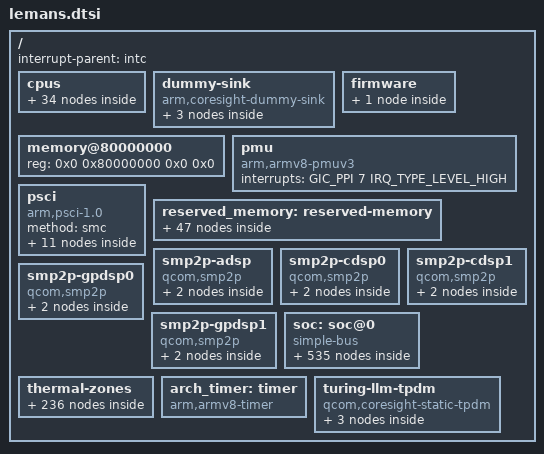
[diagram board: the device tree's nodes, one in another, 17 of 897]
// SPDX-License-Identifier: BSD-3-Clause
/*
 * Copyright (c) 2023, Linaro Limited
 * Copyright (c) 2024 Qualcomm Innovation Center, Inc. All rights reserved.
 */

#include <dt-bindings/interrupt-controller/arm-gic.h>
#include <dt-bindings/dma/qcom-gpi.h>
#include <dt-bindings/mailbox/qcom-ipcc.h>
#include <dt-bindings/firmware/qcom,scm.h>
#include <dt-bindings/soc/qcom,gpr.h>
#include <dt-bindings/thermal/qcom,pas.h>
#include <dt-bindings/thermal/thermal.h>

/ {
	interrupt-parent = <&intc>;

	#address-cells = <2>;
	#size-cells = <2>;

	cpus {
		#address-cells = <2>;
		#size-cells = <0>;

		cpu0: cpu@0 {
			device_type = "cpu";
			compatible = "qcom,kryo";
			reg = <0x0 0x0>;
			enable-method = "psci";
			power-domains = <&cpu_pd0>;
			power-domain-names = "psci";
			qcom,freq-domain = <&cpufreq_hw 0>;
			next-level-cache = <&l2_0>;
			capacity-dmips-mhz = <1024>;
			#cooling-cells = <2>;
			dynamic-power-coefficient = <100>;
			l2_0: l2-cache {
				compatible = "cache";
				cache-level = <2>;
				cache-unified;
				next-level-cache = <&l3_0>;
				l3_0: l3-cache {
					compatible = "cache";
					cache-level = <3>;
					cache-unified;
				};
			};
		};

		cpu1: cpu@100 {
			device_type = "cpu";
			compatible = "qcom,kryo";
			reg = <0x0 0x100>;
			enable-method = "psci";
			power-domains = <&cpu_pd1>;
			power-domain-names = "psci";
			qcom,freq-domain = <&cpufreq_hw 0>;
			next-level-cache = <&l2_1>;
			capacity-dmips-mhz = <1024>;
			#cooling-cells = <2>;
			dynamic-power-coefficient = <100>;
			l2_1: l2-cache {
				compatible = "cache";
				cache-level = <2>;
				cache-unified;
				next-level-cache = <&l3_0>;
			};
		};

		cpu2: cpu@200 {
			device_type = "cpu";
			compatible = "qcom,kryo";
			reg = <0x0 0x200>;
			enable-method = "psci";
			power-domains = <&cpu_pd2>;
			power-domain-names = "psci";
			qcom,freq-domain = <&cpufreq_hw 0>;
			next-level-cache = <&l2_2>;
			capacity-dmips-mhz = <1024>;
			#cooling-cells = <2>;
			dynamic-power-coefficient = <100>;
			l2_2: l2-cache {
				compatible = "cache";
				cache-level = <2>;
				cache-unified;
				next-level-cache = <&l3_0>;
			};
		};

		cpu3: cpu@300 {
			device_type = "cpu";
			compatible = "qcom,kryo";
			reg = <0x0 0x300>;
			enable-method = "psci";
			power-domains = <&cpu_pd3>;
			power-domain-names = "psci";
			qcom,freq-domain = <&cpufreq_hw 0>;
			next-level-cache = <&l2_3>;
			capacity-dmips-mhz = <1024>;
			#cooling-cells = <2>;
			dynamic-power-coefficient = <100>;
			l2_3: l2-cache {
				compatible = "cache";
				cache-level = <2>;
				cache-unified;
				next-level-cache = <&l3_0>;
			};
		};

		cpu4: cpu@10000 {
			device_type = "cpu";
			compatible = "qcom,kryo";
			reg = <0x0 0x10000>;
			enable-method = "psci";
			power-domains = <&cpu_pd4>;
			power-domain-names = "psci";
			qcom,freq-domain = <&cpufreq_hw 1>;
			next-level-cache = <&l2_4>;
			capacity-dmips-mhz = <1024>;
			#cooling-cells = <2>;
			dynamic-power-coefficient = <100>;
			l2_4: l2-cache {
				compatible = "cache";
				cache-level = <2>;
				cache-unified;
				next-level-cache = <&l3_1>;
				l3_1: l3-cache {
					compatible = "cache";
					cache-level = <3>;
					cache-unified;
				};

			};
		};

		cpu5: cpu@10100 {
			device_type = "cpu";
			compatible = "qcom,kryo";
			reg = <0x0 0x10100>;
			enable-method = "psci";
			power-domains = <&cpu_pd5>;
			power-domain-names = "psci";
			qcom,freq-domain = <&cpufreq_hw 1>;
			next-level-cache = <&l2_5>;
			capacity-dmips-mhz = <1024>;
			#cooling-cells = <2>;
			dynamic-power-coefficient = <100>;
			l2_5: l2-cache {
				compatible = "cache";
				cache-level = <2>;
				cache-unified;
				next-level-cache = <&l3_1>;
			};
		};

		cpu6: cpu@10200 {
			device_type = "cpu";
			compatible = "qcom,kryo";
			reg = <0x0 0x10200>;
			enable-method = "psci";
			power-domains = <&cpu_pd6>;
			power-domain-names = "psci";
			qcom,freq-domain = <&cpufreq_hw 1>;
			next-level-cache = <&l2_6>;
			capacity-dmips-mhz = <1024>;
			#cooling-cells = <2>;
			dynamic-power-coefficient = <100>;
			l2_6: l2-cache {
				compatible = "cache";
				cache-level = <2>;
				cache-unified;
				next-level-cache = <&l3_1>;
			};
		};

		cpu7: cpu@10300 {
			device_type = "cpu";
			compatible = "qcom,kryo";
			reg = <0x0 0x10300>;
			enable-method = "psci";
			power-domains = <&cpu_pd7>;
			power-domain-names = "psci";
			qcom,freq-domain = <&cpufreq_hw 1>;
			next-level-cache = <&l2_7>;
			capacity-dmips-mhz = <1024>;
			#cooling-cells = <2>;
			dynamic-power-coefficient = <100>;
			l2_7: l2-cache {
				compatible = "cache";
				cache-level = <2>;
				cache-unified;
				next-level-cache = <&l3_1>;
			};
		};

		cpu-map {
			cluster0 {
				core0 {
					cpu = <&cpu0>;
				};

				core1 {
					cpu = <&cpu1>;
				};

				core2 {
					cpu = <&cpu2>;
				};

				core3 {
					cpu = <&cpu3>;
				};
			};

			cluster1 {
				core0 {
					cpu = <&cpu4>;
				};

				core1 {
					cpu = <&cpu5>;
				};

				core2 {
					cpu = <&cpu6>;
				};

				core3 {
					cpu = <&cpu7>;
				};
			};
		};

		idle-states {
			entry-method = "psci";

			gold_rail_cpu_sleep_0: cpu-sleep-0 {
				compatible = "arm,idle-state";
				idle-state-name = "gold-rail-power-collapse";
				arm,psci-suspend-param = <0x40000004>;
				entry-latency-us = <702>;
				exit-latency-us = <1061>;
				min-residency-us = <4488>;
				local-timer-stop;
			};
		};

		domain-idle-states {
			cluster_sleep_gold: cluster-sleep-0 {
				compatible = "domain-idle-state";
				arm,psci-suspend-param = <0x41000044>;
				entry-latency-us = <2752>;
				exit-latency-us = <3048>;
				min-residency-us = <6118>;
			};

			cluster_sleep_apss_rsc_pc: cluster-sleep-1 {
				compatible = "domain-idle-state";
				arm,psci-suspend-param = <0x42000144>;
				entry-latency-us = <3263>;
				exit-latency-us = <6562>;
				min-residency-us = <9987>;
			};
		};
	};

	dummy-sink {
		compatible = "arm,coresight-dummy-sink";

		in-ports {
			port {
				eud_in: endpoint {
					remote-endpoint =
					<&swao_rep_out1>;
				};
			};
		};
	};

	firmware: firmware {
		scm: scm {
			compatible = "qcom,scm-sa8775p", "qcom,scm";
			qcom,dload-mode = <&tcsr 0x13000>;
			sram = <&minidump_config>;
		};
	};

	/* Will be updated by the bootloader. */
	memory@80000000 {
		device_type = "memory";
		reg = <0x0 0x80000000 0x0 0x0>;
	};

	pmu {
		compatible = "arm,armv8-pmuv3";
		interrupts = <GIC_PPI 7 IRQ_TYPE_LEVEL_HIGH>;
	};

	psci {
		compatible = "arm,psci-1.0";
		method = "smc";

		cpu_pd0: power-domain-cpu0 {
			#power-domain-cells = <0>;
			power-domains = <&cluster_0_pd>;
			domain-idle-states = <&gold_rail_cpu_sleep_0>;
		};

		cpu_pd1: power-domain-cpu1 {
			#power-domain-cells = <0>;
			power-domains = <&cluster_0_pd>;
			domain-idle-states = <&gold_rail_cpu_sleep_0>;
		};

		cpu_pd2: power-domain-cpu2 {
			#power-domain-cells = <0>;
			power-domains = <&cluster_0_pd>;
			domain-idle-states = <&gold_rail_cpu_sleep_0>;
		};

		cpu_pd3: power-domain-cpu3 {
			#power-domain-cells = <0>;
			power-domains = <&cluster_0_pd>;
			domain-idle-states = <&gold_rail_cpu_sleep_0>;
		};

		cpu_pd4: power-domain-cpu4 {
			#power-domain-cells = <0>;
			power-domains = <&cluster_1_pd>;
			domain-idle-states = <&gold_rail_cpu_sleep_0>;
		};

		cpu_pd5: power-domain-cpu5 {
			#power-domain-cells = <0>;
			power-domains = <&cluster_1_pd>;
			domain-idle-states = <&gold_rail_cpu_sleep_0>;
		};

		cpu_pd6: power-domain-cpu6 {
			#power-domain-cells = <0>;
			power-domains = <&cluster_1_pd>;
			domain-idle-states = <&gold_rail_cpu_sleep_0>;
		};

		cpu_pd7: power-domain-cpu7 {
			#power-domain-cells = <0>;
			power-domains = <&cluster_1_pd>;
			domain-idle-states = <&gold_rail_cpu_sleep_0>;
		};

		cluster_0_pd: power-domain-cluster0 {
			#power-domain-cells = <0>;
			domain-idle-states = <&cluster_sleep_gold>;
			power-domains = <&system_pd>;
		};

		cluster_1_pd: power-domain-cluster1 {
			#power-domain-cells = <0>;
			domain-idle-states = <&cluster_sleep_gold>;
			power-domains = <&system_pd>;
		};

		system_pd: power-domain-system {
			#power-domain-cells = <0>;
			domain-idle-states = <&cluster_sleep_apss_rsc_pc>;
		};
	};

	reserved_memory: reserved-memory {
		#address-cells = <2>;
		#size-cells = <2>;
		ranges;

		sail_ss_mem: sail-ss@80000000 {
			reg = <0x0 0x80000000 0x0 0x10000000>;
			no-map;
		};

		hyp_mem: hyp@90000000 {
			reg = <0x0 0x90000000 0x0 0x600000>;
			no-map;
		};

		xbl_boot_mem: xbl-boot@90600000 {
			reg = <0x0 0x90600000 0x0 0x200000>;
			no-map;
		};

		aop_image_mem: aop-image@90800000 {
			reg = <0x0 0x90800000 0x0 0x60000>;
			no-map;
		};

		aop_cmd_db_mem: aop-cmd-db@90860000 {
			compatible = "qcom,cmd-db";
			reg = <0x0 0x90860000 0x0 0x20000>;
			no-map;
		};

		uefi_log: uefi-log@908b0000 {
			reg = <0x0 0x908b0000 0x0 0x10000>;
			no-map;
		};

		ddr_training_checksum: ddr-training-checksum@908c0000 {
			reg = <0x0 0x908c0000 0x0 0x1000>;
			no-map;
		};

		reserved_mem: reserved@908f0000 {
			reg = <0x0 0x908f0000 0x0 0xe000>;
			no-map;
		};

		secdata_apss_mem: secdata-apss@908fe000 {
			reg = <0x0 0x908fe000 0x0 0x2000>;
			no-map;
		};

		smem_mem: smem@90900000 {
			compatible = "qcom,smem";
			reg = <0x0 0x90900000 0x0 0x200000>;
			no-map;
			hwlocks = <&tcsr_mutex 3>;
		};

		tz_sail_mailbox_mem: tz-sail-mailbox@90c00000 {
			reg = <0x0 0x90c00000 0x0 0x100000>;
			no-map;
		};

		sail_mailbox_mem: sail-ss@90d00000 {
			reg = <0x0 0x90d00000 0x0 0x100000>;
			no-map;
		};

		sail_ota_mem: sail-ss@90e00000 {
			reg = <0x0 0x90e00000 0x0 0x300000>;
			no-map;
		};

		gunyah_md_mem: gunyah-md@91a80000 {
			reg = <0x0 0x91a80000 0x0 0x80000>;
			no-map;
		};

		aoss_backup_mem: aoss-backup@91b00000 {
			reg = <0x0 0x91b00000 0x0 0x40000>;
			no-map;
		};

		cpucp_backup_mem: cpucp-backup@91b40000 {
			reg = <0x0 0x91b40000 0x0 0x40000>;
			no-map;
		};

		tz_config_backup_mem: tz-config-backup@91b80000 {
			reg = <0x0 0x91b80000 0x0 0x10000>;
			no-map;
		};

		ddr_training_data_mem: ddr-training-data@91b90000 {
			reg = <0x0 0x91b90000 0x0 0x10000>;
			no-map;
		};

		cdt_data_backup_mem: cdt-data-backup@91ba0000 {
			reg = <0x0 0x91ba0000 0x0 0x1000>;
			no-map;
		};

		lpass_machine_learning_mem: lpass-machine-learning@93b00000 {
			reg = <0x0 0x93b00000 0x0 0xf00000>;
			no-map;
		};

		adsp_rpc_remote_heap_mem: adsp-rpc-remote-heap@94a00000 {
			reg = <0x0 0x94a00000 0x0 0x800000>;
			no-map;
		};

		pil_camera_mem: pil-camera@95200000 {
			reg = <0x0 0x95200000 0x0 0x700000>;
			no-map;
		};

		pil_adsp_mem: pil-adsp@95900000 {
			reg = <0x0 0x95900000 0x0 0x1e00000>;
			no-map;
		};

		q6_adsp_dtb_mem: q6-adsp-dtb@97700000 {
			reg = <0x0 0x97700000 0x0 0x80000>;
			no-map;
		};

		q6_gdsp0_dtb_mem: q6-gdsp0-dtb@97780000 {
			reg = <0x0 0x97780000 0x0 0x80000>;
			no-map;
		};

		pil_gdsp0_mem: pil-gdsp0@97800000 {
			reg = <0x0 0x97800000 0x0 0x1e00000>;
			no-map;
		};

		pil_gdsp1_mem: pil-gdsp1@99600000 {
			reg = <0x0 0x99600000 0x0 0x1e00000>;
			no-map;
		};

		q6_gdsp1_dtb_mem: q6-gdsp1-dtb@9b400000 {
			reg = <0x0 0x9b400000 0x0 0x80000>;
			no-map;
		};

		q6_cdsp0_dtb_mem: q6-cdsp0-dtb@9b480000 {
			reg = <0x0 0x9b480000 0x0 0x80000>;
			no-map;
		};

		pil_cdsp0_mem: pil-cdsp0@9b500000 {
			reg = <0x0 0x9b500000 0x0 0x1e00000>;
			no-map;
		};

		pil_gpu_mem: pil-gpu@9d300000 {
			reg = <0x0 0x9d300000 0x0 0x2000>;
			no-map;
		};

		q6_cdsp1_dtb_mem: q6-cdsp1-dtb@9d380000 {
			reg = <0x0 0x9d380000 0x0 0x80000>;
			no-map;
		};

		pil_cdsp1_mem: pil-cdsp1@9d400000 {
			reg = <0x0 0x9d400000 0x0 0x1e00000>;
			no-map;
		};

		pil_cvp_mem: pil-cvp@9f200000 {
			reg = <0x0 0x9f200000 0x0 0x700000>;
			no-map;
		};

		pil_video_mem: pil-video@9f900000 {
			reg = <0x0 0x9f900000 0x0 0x1000000>;
			no-map;
		};

		firmware_mem: firmware-region@b0000000 {
			reg = <0x0 0xb0000000 0x0 0x800000>;
			no-map;
		};

		scmi_mem: scmi-region@d0000000 {
			reg = <0x0 0xd0000000 0x0 0x40000>;
			no-map;
		};

		firmware_logs_mem: firmware-logs@d0040000 {
			reg = <0x0 0xd0040000 0x0 0x10000>;
			no-map;
		};

		firmware_audio_mem: firmware-audio@d0050000 {
			reg = <0x0 0xd0050000 0x0 0x4000>;
			no-map;
		};

		firmware_reserved_mem: firmware-reserved@d0054000 {
			reg = <0x0 0xd0054000 0x0 0x9c000>;
			no-map;
		};

		firmware_quantum_test_mem: firmware-quantum-test@d00f0000 {
			reg = <0x0 0xd00f0000 0x0 0x10000>;
			no-map;
		};

		tags_mem: tags@d0100000 {
			reg = <0x0 0xd0100000 0x0 0x1200000>;
			no-map;
		};

		qtee_mem: qtee@d1300000 {
			reg = <0x0 0xd1300000 0x0 0x500000>;
			no-map;
		};

		deepsleep_backup_mem: deepsleep-backup@d1800000 {
			reg = <0x0 0xd1800000 0x0 0x100000>;
			no-map;
		};

		trusted_apps_mem: trusted-apps@d1900000 {
			reg = <0x0 0xd1900000 0x0 0x1c00000>;
			no-map;
		};

		tz_stat_mem: tz-stat@db100000 {
			reg = <0x0 0xdb100000 0x0 0x100000>;
			no-map;
		};

		cpucp_fw_mem: cpucp-fw@db200000 {
			reg = <0x0 0xdb200000 0x0 0x100000>;
			no-map;
		};
	};

	smp2p-adsp {
		compatible = "qcom,smp2p";
		qcom,smem = <443>, <429>;
		interrupts-extended = <&ipcc IPCC_CLIENT_LPASS
					     IPCC_MPROC_SIGNAL_SMP2P
					     IRQ_TYPE_EDGE_RISING>;
		mboxes = <&ipcc IPCC_CLIENT_LPASS IPCC_MPROC_SIGNAL_SMP2P>;

		qcom,local-pid = <0>;
		qcom,remote-pid = <2>;

		smp2p_adsp_out: master-kernel {
			qcom,entry-name = "master-kernel";
			#qcom,smem-state-cells = <1>;
		};

		smp2p_adsp_in: slave-kernel {
			qcom,entry-name = "slave-kernel";
			interrupt-controller;
			#interrupt-cells = <2>;
		};
	};

	smp2p-cdsp0 {
		compatible = "qcom,smp2p";
		qcom,smem = <94>, <432>;
		interrupts-extended = <&ipcc IPCC_CLIENT_CDSP
					     IPCC_MPROC_SIGNAL_SMP2P
					     IRQ_TYPE_EDGE_RISING>;
		mboxes = <&ipcc IPCC_CLIENT_CDSP IPCC_MPROC_SIGNAL_SMP2P>;

		qcom,local-pid = <0>;
		qcom,remote-pid = <5>;

		smp2p_cdsp0_out: master-kernel {
			qcom,entry-name = "master-kernel";
			#qcom,smem-state-cells = <1>;
		};

		smp2p_cdsp0_in: slave-kernel {
			qcom,entry-name = "slave-kernel";
			interrupt-controller;
			#interrupt-cells = <2>;
		};
	};

	smp2p-cdsp1 {
		compatible = "qcom,smp2p";
		qcom,smem = <617>, <616>;
		interrupts-extended = <&ipcc IPCC_CLIENT_NSP1
					     IPCC_MPROC_SIGNAL_SMP2P
					     IRQ_TYPE_EDGE_RISING>;
		mboxes = <&ipcc IPCC_CLIENT_NSP1 IPCC_MPROC_SIGNAL_SMP2P>;

		qcom,local-pid = <0>;
		qcom,remote-pid = <12>;

		smp2p_cdsp1_out: master-kernel {
			qcom,entry-name = "master-kernel";
			#qcom,smem-state-cells = <1>;
		};

		smp2p_cdsp1_in: slave-kernel {
			qcom,entry-name = "slave-kernel";
			interrupt-controller;
			#interrupt-cells = <2>;
		};
	};

	smp2p-gpdsp0 {
		compatible = "qcom,smp2p";
		qcom,smem = <617>, <616>;
		interrupts-extended = <&ipcc IPCC_CLIENT_GPDSP0
					     IPCC_MPROC_SIGNAL_SMP2P
					     IRQ_TYPE_EDGE_RISING>;
		mboxes = <&ipcc IPCC_CLIENT_GPDSP0 IPCC_MPROC_SIGNAL_SMP2P>;

		qcom,local-pid = <0>;
		qcom,remote-pid = <17>;

		smp2p_gpdsp0_out: master-kernel {
			qcom,entry-name = "master-kernel";
			#qcom,smem-state-cells = <1>;
		};

		smp2p_gpdsp0_in: slave-kernel {
			qcom,entry-name = "slave-kernel";
			interrupt-controller;
			#interrupt-cells = <2>;
		};
	};

	smp2p-gpdsp1 {
		compatible = "qcom,smp2p";
		qcom,smem = <617>, <616>;
		interrupts-extended = <&ipcc IPCC_CLIENT_GPDSP1
					     IPCC_MPROC_SIGNAL_SMP2P
					     IRQ_TYPE_EDGE_RISING>;
		mboxes = <&ipcc IPCC_CLIENT_GPDSP1 IPCC_MPROC_SIGNAL_SMP2P>;

		qcom,local-pid = <0>;
		qcom,remote-pid = <18>;

		smp2p_gpdsp1_out: master-kernel {
			qcom,entry-name = "master-kernel";
			#qcom,smem-state-cells = <1>;
		};

		smp2p_gpdsp1_in: slave-kernel {
			qcom,entry-name = "slave-kernel";
			interrupt-controller;
			#interrupt-cells = <2>;
		};
	};

	soc: soc@0 {
		compatible = "simple-bus";
		#address-cells = <2>;
		#size-cells = <2>;
		ranges = <0 0 0 0 0x10 0>;

		ipcc: mailbox@408000 {
			compatible = "qcom,sa8775p-ipcc", "qcom,ipcc";
			reg = <0x0 0x00408000 0x0 0x1000>;
			interrupts = <GIC_SPI 229 IRQ_TYPE_LEVEL_HIGH>;
			interrupt-controller;
			#interrupt-cells = <3>;
			#mbox-cells = <2>;
		};

		qfprom: efuse@784000 {
			compatible = "qcom,sa8775p-qfprom", "qcom,qfprom";
			reg = <0x0 0x00784000 0x0 0x3000>;
			#address-cells = <1>;
			#size-cells = <1>;

			gpu_speed_bin: gpu-speed-bin@240c {
				reg = <0x240c 0x1>;
				bits = <0 8>;
			};
		};

		gpi_dma2: dma-controller@800000 {
			compatible = "qcom,sa8775p-gpi-dma", "qcom,sm6350-gpi-dma";
			reg = <0x0 0x00800000 0x0 0x60000>;
			#dma-cells = <3>;
			interrupts = <GIC_SPI 588 IRQ_TYPE_LEVEL_HIGH>,
				     <GIC_SPI 589 IRQ_TYPE_LEVEL_HIGH>,
				     <GIC_SPI 590 IRQ_TYPE_LEVEL_HIGH>,
				     <GIC_SPI 591 IRQ_TYPE_LEVEL_HIGH>,
				     <GIC_SPI 592 IRQ_TYPE_LEVEL_HIGH>,
				     <GIC_SPI 593 IRQ_TYPE_LEVEL_HIGH>,
				     <GIC_SPI 594 IRQ_TYPE_LEVEL_HIGH>,
				     <GIC_SPI 595 IRQ_TYPE_LEVEL_HIGH>,
				     <GIC_SPI 596 IRQ_TYPE_LEVEL_HIGH>,
				     <GIC_SPI 597 IRQ_TYPE_LEVEL_HIGH>,
				     <GIC_SPI 598 IRQ_TYPE_LEVEL_HIGH>,
				     <GIC_SPI 599 IRQ_TYPE_LEVEL_HIGH>;
			dma-channels = <12>;
			dma-channel-mask = <0xfff>;
			iommus = <&apps_smmu 0x5b6 0x0>;
			status = "disabled";
		};

		qupv3_id_2: geniqup@8c0000 {
			compatible = "qcom,geni-se-qup";
			reg = <0x0 0x008c0000 0x0 0x6000>;
			ranges;
			iommus = <&apps_smmu 0x5a3 0x0>;
			#address-cells = <2>;
			#size-cells = <2>;
			status = "disabled";

			i2c14: i2c@880000 {
				compatible = "qcom,geni-i2c";
				reg = <0x0 0x880000 0x0 0x4000>;
				#address-cells = <1>;
				#size-cells = <0>;
				interrupts = <GIC_SPI 373 IRQ_TYPE_LEVEL_HIGH>;
				dmas = <&gpi_dma2 0 0 QCOM_GPI_I2C>,
				       <&gpi_dma2 1 0 QCOM_GPI_I2C>;
				dma-names = "tx",
					    "rx";
				status = "disabled";
			};

			spi14: spi@880000 {
				compatible = "qcom,geni-spi";
				reg = <0x0 0x880000 0x0 0x4000>;
				#address-cells = <1>;
				#size-cells = <0>;
				interrupts = <GIC_SPI 373 IRQ_TYPE_LEVEL_HIGH>;
				dmas = <&gpi_dma2 0 0 QCOM_GPI_SPI>,
				       <&gpi_dma2 1 0 QCOM_GPI_SPI>;
				dma-names = "tx",
					    "rx";
				status = "disabled";
			};

			uart14: serial@880000 {
				compatible = "qcom,geni-uart";
				reg = <0x0 0x00880000 0x0 0x4000>;
				interrupts = <GIC_SPI 373 IRQ_TYPE_LEVEL_HIGH>;
				status = "disabled";
			};

			i2c15: i2c@884000 {
				compatible = "qcom,geni-i2c";
				reg = <0x0 0x884000 0x0 0x4000>;
				#address-cells = <1>;
				#size-cells = <0>;
				interrupts = <GIC_SPI 583 IRQ_TYPE_LEVEL_HIGH>;
				dmas = <&gpi_dma2 0 1 QCOM_GPI_I2C>,
				       <&gpi_dma2 1 1 QCOM_GPI_I2C>;
				dma-names = "tx",
					    "rx";
				status = "disabled";
			};

			spi15: spi@884000 {
				compatible = "qcom,geni-spi";
				reg = <0x0 0x884000 0x0 0x4000>;
				#address-cells = <1>;
				#size-cells = <0>;
				interrupts = <GIC_SPI 583 IRQ_TYPE_LEVEL_HIGH>;
				dmas = <&gpi_dma2 0 1 QCOM_GPI_SPI>,
				       <&gpi_dma2 1 1 QCOM_GPI_SPI>;
				dma-names = "tx",
					    "rx";
				status = "disabled";
			};

			uart15: serial@884000 {
				compatible = "qcom,geni-uart";
				reg = <0x0 0x00884000 0x0 0x4000>;
				interrupts = <GIC_SPI 583 IRQ_TYPE_LEVEL_HIGH>;
				status = "disabled";
			};

			i2c16: i2c@888000 {
				compatible = "qcom,geni-i2c";
				reg = <0x0 0x888000 0x0 0x4000>;
				#address-cells = <1>;
				#size-cells = <0>;
				interrupts = <GIC_SPI 584 IRQ_TYPE_LEVEL_HIGH>;
				dmas = <&gpi_dma2 0 2 QCOM_GPI_I2C>,
				       <&gpi_dma2 1 2 QCOM_GPI_I2C>;
				dma-names = "tx",
					    "rx";
				status = "disabled";
			};

			spi16: spi@888000 {
				compatible = "qcom,geni-spi";
				reg = <0x0 0x00888000 0x0 0x4000>;
				interrupts = <GIC_SPI 584 IRQ_TYPE_LEVEL_HIGH>;
				dmas = <&gpi_dma2 0 2 QCOM_GPI_SPI>,
				       <&gpi_dma2 1 2 QCOM_GPI_SPI>;
				dma-names = "tx",
					    "rx";
				#address-cells = <1>;
				#size-cells = <0>;
				status = "disabled";
			};

			uart16: serial@888000 {
				compatible = "qcom,geni-uart";
				reg = <0x0 0x00888000 0x0 0x4000>;
				interrupts = <GIC_SPI 584 IRQ_TYPE_LEVEL_HIGH>;
				status = "disabled";
			};

			i2c17: i2c@88c000 {
				compatible = "qcom,geni-i2c";
				reg = <0x0 0x88c000 0x0 0x4000>;
				#address-cells = <1>;
				#size-cells = <0>;
				interrupts = <GIC_SPI 585 IRQ_TYPE_LEVEL_HIGH>;
				dmas = <&gpi_dma2 0 3 QCOM_GPI_I2C>,
				       <&gpi_dma2 1 3 QCOM_GPI_I2C>;
				dma-names = "tx",
					    "rx";
				status = "disabled";
			};

			spi17: spi@88c000 {
				compatible = "qcom,geni-spi";
				reg = <0x0 0x88c000 0x0 0x4000>;
				#address-cells = <1>;
				#size-cells = <0>;
				interrupts = <GIC_SPI 585 IRQ_TYPE_LEVEL_HIGH>;
				dmas = <&gpi_dma2 0 3 QCOM_GPI_SPI>,
				       <&gpi_dma2 1 3 QCOM_GPI_SPI>;
				dma-names = "tx",
					    "rx";
				status = "disabled";
			};

			uart17: serial@88c000 {
				compatible = "qcom,geni-uart";
				reg = <0x0 0x0088c000 0x0 0x4000>;
				interrupts = <GIC_SPI 585 IRQ_TYPE_LEVEL_HIGH>;
				status = "disabled";
			};

			i2c18: i2c@890000 {
				compatible = "qcom,geni-i2c";
				reg = <0x0 0x00890000 0x0 0x4000>;
				interrupts = <GIC_SPI 586 IRQ_TYPE_LEVEL_HIGH>;
				dmas = <&gpi_dma2 0 4 QCOM_GPI_I2C>,
				       <&gpi_dma2 1 4 QCOM_GPI_I2C>;
				dma-names = "tx",
					    "rx";
				#address-cells = <1>;
				#size-cells = <0>;
				status = "disabled";
			};

			spi18: spi@890000 {
				compatible = "qcom,geni-spi";
				reg = <0x0 0x890000 0x0 0x4000>;
				#address-cells = <1>;
				#size-cells = <0>;
				interrupts = <GIC_SPI 586 IRQ_TYPE_LEVEL_HIGH>;
				dmas = <&gpi_dma2 0 4 QCOM_GPI_SPI>,
				       <&gpi_dma2 1 4 QCOM_GPI_SPI>;
				dma-names = "tx",
					    "rx";
				status = "disabled";
			};

			uart18: serial@890000 {
				compatible = "qcom,geni-uart";
				reg = <0x0 0x00890000 0x0 0x4000>;
				interrupts = <GIC_SPI 586 IRQ_TYPE_LEVEL_HIGH>;
				status = "disabled";
			};

			i2c19: i2c@894000 {
				compatible = "qcom,geni-i2c";
				reg = <0x0 0x894000 0x0 0x4000>;
				#address-cells = <1>;
				#size-cells = <0>;
				interrupts = <GIC_SPI 587 IRQ_TYPE_LEVEL_HIGH>;
				dmas = <&gpi_dma2 0 5 QCOM_GPI_I2C>,
				       <&gpi_dma2 1 5 QCOM_GPI_I2C>;
				dma-names = "tx",
					    "rx";
				status = "disabled";
			};

			spi19: spi@894000 {
				compatible = "qcom,geni-spi";
				reg = <0x0 0x894000 0x0 0x4000>;
				#address-cells = <1>;
				#size-cells = <0>;
				interrupts = <GIC_SPI 587 IRQ_TYPE_LEVEL_HIGH>;
				dmas = <&gpi_dma2 0 5 QCOM_GPI_SPI>,
				       <&gpi_dma2 1 5 QCOM_GPI_SPI>;
				dma-names = "tx",
					    "rx";
				status = "disabled";
			};

			uart19: serial@894000 {
				compatible = "qcom,geni-uart";
				reg = <0x0 0x00894000 0x0 0x4000>;
				interrupts = <GIC_SPI 587 IRQ_TYPE_LEVEL_HIGH>;
				status = "disabled";
			};

			i2c20: i2c@898000 {
				compatible = "qcom,geni-i2c";
				reg = <0x0 0x898000 0x0 0x4000>;
				#address-cells = <1>;
				#size-cells = <0>;
				interrupts = <GIC_SPI 833 IRQ_TYPE_LEVEL_HIGH>;
				dmas = <&gpi_dma2 0 6 QCOM_GPI_I2C>,
				       <&gpi_dma2 1 6 QCOM_GPI_I2C>;
				dma-names = "tx",
					    "rx";
				status = "disabled";
			};

			spi20: spi@898000 {
				compatible = "qcom,geni-spi";
				reg = <0x0 0x898000 0x0 0x4000>;
				#address-cells = <1>;
				#size-cells = <0>;
				interrupts = <GIC_SPI 833 IRQ_TYPE_LEVEL_HIGH>;
				dmas = <&gpi_dma2 0 6 QCOM_GPI_SPI>,
				       <&gpi_dma2 1 6 QCOM_GPI_SPI>;
				dma-names = "tx",
					    "rx";
				status = "disabled";
			};

			uart20: serial@898000 {
				compatible = "qcom,geni-uart";
				reg = <0x0 0x00898000 0x0 0x4000>;
				interrupts = <GIC_SPI 833 IRQ_TYPE_LEVEL_HIGH>;
				status = "disabled";
			};

		};

		gpi_dma0: dma-controller@900000 {
			compatible = "qcom,sa8775p-gpi-dma", "qcom,sm6350-gpi-dma";
			reg = <0x0 0x00900000 0x0 0x60000>;
			#dma-cells = <3>;
			interrupts = <GIC_SPI 244 IRQ_TYPE_LEVEL_HIGH>,
				     <GIC_SPI 245 IRQ_TYPE_LEVEL_HIGH>,
				     <GIC_SPI 246 IRQ_TYPE_LEVEL_HIGH>,
				     <GIC_SPI 247 IRQ_TYPE_LEVEL_HIGH>,
				     <GIC_SPI 248 IRQ_TYPE_LEVEL_HIGH>,
				     <GIC_SPI 249 IRQ_TYPE_LEVEL_HIGH>,
				     <GIC_SPI 250 IRQ_TYPE_LEVEL_HIGH>,
				     <GIC_SPI 251 IRQ_TYPE_LEVEL_HIGH>,
				     <GIC_SPI 252 IRQ_TYPE_LEVEL_HIGH>,
				     <GIC_SPI 253 IRQ_TYPE_LEVEL_HIGH>,
				     <GIC_SPI 254 IRQ_TYPE_LEVEL_HIGH>,
				     <GIC_SPI 255 IRQ_TYPE_LEVEL_HIGH>;
			dma-channels = <12>;
			dma-channel-mask = <0xfff>;
			iommus = <&apps_smmu 0x416 0x0>;
			status = "disabled";
		};

		qupv3_id_0: geniqup@9c0000 {
			compatible = "qcom,geni-se-qup";
			reg = <0x0 0x9c0000 0x0 0x6000>;
			#address-cells = <2>;
			#size-cells = <2>;
			ranges;
			iommus = <&apps_smmu 0x403 0x0>;
			status = "disabled";

			i2c0: i2c@980000 {
				compatible = "qcom,geni-i2c";
				reg = <0x0 0x980000 0x0 0x4000>;
				#address-cells = <1>;
				#size-cells = <0>;
				interrupts = <GIC_SPI 550 IRQ_TYPE_LEVEL_HIGH>;
				dmas = <&gpi_dma0 0 0 QCOM_GPI_I2C>,
				       <&gpi_dma0 1 0 QCOM_GPI_I2C>;
				dma-names = "tx",
					    "rx";
				status = "disabled";
			};

			spi0: spi@980000 {
				compatible = "qcom,geni-spi";
				reg = <0x0 0x980000 0x0 0x4000>;
				#address-cells = <1>;
				#size-cells = <0>;
				interrupts = <GIC_SPI 550 IRQ_TYPE_LEVEL_HIGH>;
				dmas = <&gpi_dma0 0 0 QCOM_GPI_SPI>,
				     <&gpi_dma0 1 0 QCOM_GPI_SPI>;
				dma-names = "tx",
					    "rx";
				status = "disabled";
			};

			uart0: serial@980000 {
				compatible = "qcom,geni-uart";
				reg = <0x0 0x980000 0x0 0x4000>;
				interrupts = <GIC_SPI 550 IRQ_TYPE_LEVEL_HIGH>;
				status = "disabled";
			};

			i2c1: i2c@984000 {
				compatible = "qcom,geni-i2c";
				reg = <0x0 0x984000 0x0 0x4000>;
				#address-cells = <1>;
				#size-cells = <0>;
				interrupts = <GIC_SPI 551 IRQ_TYPE_LEVEL_HIGH>;
				dmas = <&gpi_dma0 0 1 QCOM_GPI_I2C>,
				       <&gpi_dma0 1 1 QCOM_GPI_I2C>;
				dma-names = "tx",
					    "rx";
				status = "disabled";
			};

			spi1: spi@984000 {
				compatible = "qcom,geni-spi";
				reg = <0x0 0x984000 0x0 0x4000>;
				#address-cells = <1>;
				#size-cells = <0>;
				interrupts = <GIC_SPI 551 IRQ_TYPE_LEVEL_HIGH>;
				dmas = <&gpi_dma0 0 1 QCOM_GPI_SPI>,
				       <&gpi_dma0 1 1 QCOM_GPI_SPI>;
				dma-names = "tx",
					    "rx";
				status = "disabled";
			};

			uart1: serial@984000 {
				compatible = "qcom,geni-uart";
				reg = <0x0 0x984000 0x0 0x4000>;
				interrupts = <GIC_SPI 551 IRQ_TYPE_LEVEL_HIGH>;
				status = "disabled";
			};

			i2c2: i2c@988000 {
				compatible = "qcom,geni-i2c";
				reg = <0x0 0x988000 0x0 0x4000>;
				#address-cells = <1>;
				#size-cells = <0>;
				interrupts = <GIC_SPI 529 IRQ_TYPE_LEVEL_HIGH>;
				dmas = <&gpi_dma0 0 2 QCOM_GPI_I2C>,
				       <&gpi_dma0 1 2 QCOM_GPI_I2C>;
				dma-names = "tx",
					    "rx";
				status = "disabled";
			};

			spi2: spi@988000 {
				compatible = "qcom,geni-spi";
				reg = <0x0 0x988000 0x0 0x4000>;
				#address-cells = <1>;
				#size-cells = <0>;
				interrupts = <GIC_SPI 529 IRQ_TYPE_LEVEL_HIGH>;
				dmas = <&gpi_dma0 0 2 QCOM_GPI_SPI>,
				       <&gpi_dma0 1 2 QCOM_GPI_SPI>;
				dma-names = "tx",
					    "rx";
				status = "disabled";
			};

			uart2: serial@988000 {
				compatible = "qcom,geni-uart";
				reg = <0x0 0x988000 0x0 0x4000>;
				interrupts = <GIC_SPI 529 IRQ_TYPE_LEVEL_HIGH>;
				status = "disabled";
			};

			i2c3: i2c@98c000 {
				compatible = "qcom,geni-i2c";
				reg = <0x0 0x98c000 0x0 0x4000>;
				#address-cells = <1>;
				#size-cells = <0>;
				interrupts = <GIC_SPI 530 IRQ_TYPE_LEVEL_HIGH>;
				dmas = <&gpi_dma0 0 3 QCOM_GPI_I2C>,
				       <&gpi_dma0 1 3 QCOM_GPI_I2C>;
				dma-names = "tx",
					    "rx";
				status = "disabled";
			};

			spi3: spi@98c000 {
				compatible = "qcom,geni-spi";
				reg = <0x0 0x98c000 0x0 0x4000>;
				#address-cells = <1>;
				#size-cells = <0>;
				interrupts = <GIC_SPI 530 IRQ_TYPE_LEVEL_HIGH>;
				dmas = <&gpi_dma0 0 3 QCOM_GPI_SPI>,
				       <&gpi_dma0 1 3 QCOM_GPI_SPI>;
				dma-names = "tx",
					    "rx";
				status = "disabled";
			};

			uart3: serial@98c000 {
				compatible = "qcom,geni-uart";
				reg = <0x0 0x98c000 0x0 0x4000>;
				interrupts = <GIC_SPI 530 IRQ_TYPE_LEVEL_HIGH>;
				status = "disabled";
			};

			i2c4: i2c@990000 {
				compatible = "qcom,geni-i2c";
				reg = <0x0 0x990000 0x0 0x4000>;
				#address-cells = <1>;
				#size-cells = <0>;
				interrupts = <GIC_SPI 531 IRQ_TYPE_LEVEL_HIGH>;
				dmas = <&gpi_dma0 0 4 QCOM_GPI_I2C>,
				       <&gpi_dma0 1 4 QCOM_GPI_I2C>;
				dma-names = "tx",
					    "rx";
				status = "disabled";
			};

			spi4: spi@990000 {
				compatible = "qcom,geni-spi";
				reg = <0x0 0x990000 0x0 0x4000>;
				#address-cells = <1>;
				#size-cells = <0>;
				interrupts = <GIC_SPI 531 IRQ_TYPE_LEVEL_HIGH>;
				dmas = <&gpi_dma0 0 4 QCOM_GPI_SPI>,
				       <&gpi_dma0 1 4 QCOM_GPI_SPI>;
				dma-names = "tx",
					    "rx";
				status = "disabled";
			};

			uart4: serial@990000 {
				compatible = "qcom,geni-uart";
				reg = <0x0 0x990000 0x0 0x4000>;
				interrupts = <GIC_SPI 531 IRQ_TYPE_LEVEL_HIGH>;
				status = "disabled";
			};

			i2c5: i2c@994000 {
				compatible = "qcom,geni-i2c";
				reg = <0x0 0x994000 0x0 0x4000>;
				#address-cells = <1>;
				#size-cells = <0>;
				interrupts = <GIC_SPI 535 IRQ_TYPE_LEVEL_HIGH>;
				dmas = <&gpi_dma0 0 5 QCOM_GPI_I2C>,
				       <&gpi_dma0 1 5 QCOM_GPI_I2C>;
				dma-names = "tx",
					    "rx";
				status = "disabled";
			};

			spi5: spi@994000 {
				compatible = "qcom,geni-spi";
				reg = <0x0 0x994000 0x0 0x4000>;
				#address-cells = <1>;
				#size-cells = <0>;
				interrupts = <GIC_SPI 535 IRQ_TYPE_LEVEL_HIGH>;
				dmas = <&gpi_dma0 0 5 QCOM_GPI_SPI>,
				       <&gpi_dma0 1 5 QCOM_GPI_SPI>;
				dma-names = "tx",
					    "rx";
				status = "disabled";
			};

			uart5: serial@994000 {
				compatible = "qcom,geni-uart";
				reg = <0x0 0x994000 0x0 0x4000>;
				interrupts = <GIC_SPI 535 IRQ_TYPE_LEVEL_HIGH>;
				status = "disabled";
			};
		};

		gpi_dma1: dma-controller@a00000 {
			compatible = "qcom,sa8775p-gpi-dma", "qcom,sm6350-gpi-dma";
			reg = <0x0 0x00a00000 0x0 0x60000>;
			#dma-cells = <3>;
			interrupts = <GIC_SPI 279 IRQ_TYPE_LEVEL_HIGH>,
				     <GIC_SPI 280 IRQ_TYPE_LEVEL_HIGH>,
				     <GIC_SPI 281 IRQ_TYPE_LEVEL_HIGH>,
				     <GIC_SPI 282 IRQ_TYPE_LEVEL_HIGH>,
				     <GIC_SPI 283 IRQ_TYPE_LEVEL_HIGH>,
				     <GIC_SPI 284 IRQ_TYPE_LEVEL_HIGH>,
				     <GIC_SPI 293 IRQ_TYPE_LEVEL_HIGH>,
				     <GIC_SPI 294 IRQ_TYPE_LEVEL_HIGH>,
				     <GIC_SPI 295 IRQ_TYPE_LEVEL_HIGH>,
				     <GIC_SPI 296 IRQ_TYPE_LEVEL_HIGH>,
				     <GIC_SPI 297 IRQ_TYPE_LEVEL_HIGH>,
				     <GIC_SPI 298 IRQ_TYPE_LEVEL_HIGH>;
			iommus = <&apps_smmu 0x456 0x0>;
			dma-channels = <12>;
			dma-channel-mask = <0xfff>;
			status = "disabled";
		};

		qupv3_id_1: geniqup@ac0000 {
			compatible = "qcom,geni-se-qup";
			reg = <0x0 0x00ac0000 0x0 0x6000>;
			#address-cells = <2>;
			#size-cells = <2>;
			ranges;
			iommus = <&apps_smmu 0x443 0x0>;
			status = "disabled";

			i2c7: i2c@a80000 {
				compatible = "qcom,geni-i2c";
				reg = <0x0 0xa80000 0x0 0x4000>;
				#address-cells = <1>;
				#size-cells = <0>;
				interrupts = <GIC_SPI 353 IRQ_TYPE_LEVEL_HIGH>;
				dmas = <&gpi_dma1 0 0 QCOM_GPI_I2C>,
				       <&gpi_dma1 1 0 QCOM_GPI_I2C>;
				dma-names = "tx",
					    "rx";
				status = "disabled";
			};

			spi7: spi@a80000 {
				compatible = "qcom,geni-spi";
				reg = <0x0 0xa80000 0x0 0x4000>;
				#address-cells = <1>;
				#size-cells = <0>;
				interrupts = <GIC_SPI 353 IRQ_TYPE_LEVEL_HIGH>;
				dmas = <&gpi_dma1 0 0 QCOM_GPI_SPI>,
				       <&gpi_dma1 1 0 QCOM_GPI_SPI>;
				dma-names = "tx",
					    "rx";
				status = "disabled";
			};

			uart7: serial@a80000 {
				compatible = "qcom,geni-uart";
				reg = <0x0 0x00a80000 0x0 0x4000>;
				interrupts = <GIC_SPI 353 IRQ_TYPE_LEVEL_HIGH>;
				status = "disabled";
			};

			i2c8: i2c@a84000 {
				compatible = "qcom,geni-i2c";
				reg = <0x0 0xa84000 0x0 0x4000>;
				#address-cells = <1>;
				#size-cells = <0>;
				interrupts = <GIC_SPI 354 IRQ_TYPE_LEVEL_HIGH>;
				dmas = <&gpi_dma1 0 1 QCOM_GPI_I2C>,
				       <&gpi_dma1 1 1 QCOM_GPI_I2C>;
				dma-names = "tx",
					    "rx";
				status = "disabled";
			};

			spi8: spi@a84000 {
				compatible = "qcom,geni-spi";
				reg = <0x0 0xa84000 0x0 0x4000>;
				#address-cells = <1>;
				#size-cells = <0>;
				interrupts = <GIC_SPI 354 IRQ_TYPE_LEVEL_HIGH>;
				dmas = <&gpi_dma1 0 1 QCOM_GPI_SPI>,
				       <&gpi_dma1 1 1 QCOM_GPI_SPI>;
				dma-names = "tx",
					    "rx";
				status = "disabled";
			};

			uart8: serial@a84000 {
				compatible = "qcom,geni-uart";
				reg = <0x0 0x00a84000 0x0 0x4000>;
				interrupts = <GIC_SPI 354 IRQ_TYPE_LEVEL_HIGH>;
				status = "disabled";
			};

			i2c9: i2c@a88000 {
				compatible = "qcom,geni-i2c";
				reg = <0x0 0xa88000 0x0 0x4000>;
				#address-cells = <1>;
				#size-cells = <0>;
				interrupts = <GIC_SPI 355 IRQ_TYPE_LEVEL_HIGH>;
				dmas = <&gpi_dma1 0 2 QCOM_GPI_I2C>,
				       <&gpi_dma1 1 2 QCOM_GPI_I2C>;
				dma-names = "tx",
					    "rx";
				status = "disabled";
			};

			spi9: spi@a88000 {
				compatible = "qcom,geni-spi";
				reg = <0x0 0xa88000 0x0 0x4000>;
				#address-cells = <1>;
				#size-cells = <0>;
				interrupts = <GIC_SPI 355 IRQ_TYPE_LEVEL_HIGH>;
				dmas = <&gpi_dma1 0 2 QCOM_GPI_SPI>,
				       <&gpi_dma1 1 2 QCOM_GPI_SPI>;
				dma-names = "tx",
					    "rx";
				status = "disabled";
			};

			uart9: serial@a88000 {
				compatible = "qcom,geni-uart";
				reg = <0x0 0xa88000 0x0 0x4000>;
				interrupts = <GIC_SPI 355 IRQ_TYPE_LEVEL_HIGH>;
				status = "disabled";
			};

			i2c10: i2c@a8c000 {
				compatible = "qcom,geni-i2c";
				reg = <0x0 0xa8c000 0x0 0x4000>;
				#address-cells = <1>;
				#size-cells = <0>;
				interrupts = <GIC_SPI 356 IRQ_TYPE_LEVEL_HIGH>;
				dmas = <&gpi_dma1 0 3 QCOM_GPI_I2C>,
				       <&gpi_dma1 1 3 QCOM_GPI_I2C>;
				dma-names = "tx",
					    "rx";
				status = "disabled";
			};

			spi10: spi@a8c000 {
				compatible = "qcom,geni-spi";
				reg = <0x0 0xa8c000 0x0 0x4000>;
				#address-cells = <1>;
				#size-cells = <0>;
				interrupts = <GIC_SPI 356 IRQ_TYPE_LEVEL_HIGH>;
				dmas = <&gpi_dma1 0 3 QCOM_GPI_SPI>,
				       <&gpi_dma1 1 3 QCOM_GPI_SPI>;
				dma-names = "tx",
					    "rx";
				status = "disabled";
			};

			uart10: serial@a8c000 {
				compatible = "qcom,geni-uart";
				reg = <0x0 0x00a8c000 0x0 0x4000>;
				interrupts = <GIC_SPI 356 IRQ_TYPE_LEVEL_HIGH>;
				status = "disabled";
			};

			i2c11: i2c@a90000 {
				compatible = "qcom,geni-i2c";
				reg = <0x0 0xa90000 0x0 0x4000>;
				#address-cells = <1>;
				#size-cells = <0>;
				interrupts = <GIC_SPI 357 IRQ_TYPE_LEVEL_HIGH>;
				dmas = <&gpi_dma1 0 4 QCOM_GPI_I2C>,
				       <&gpi_dma1 1 4 QCOM_GPI_I2C>;
				dma-names = "tx",
					    "rx";
				status = "disabled";
			};

			spi11: spi@a90000 {
				compatible = "qcom,geni-spi";
				reg = <0x0 0xa90000 0x0 0x4000>;
				#address-cells = <1>;
				#size-cells = <0>;
				interrupts = <GIC_SPI 357 IRQ_TYPE_LEVEL_HIGH>;
				dmas = <&gpi_dma1 0 4 QCOM_GPI_SPI>,
				       <&gpi_dma1 1 4 QCOM_GPI_SPI>;
				dma-names = "tx",
					    "rx";
				status = "disabled";
			};

			uart11: serial@a90000 {
				compatible = "qcom,geni-uart";
				reg = <0x0 0x00a90000 0x0 0x4000>;
				interrupts = <GIC_SPI 357 IRQ_TYPE_LEVEL_HIGH>;
				status = "disabled";
			};

			i2c12: i2c@a94000 {
				compatible = "qcom,geni-i2c";
				reg = <0x0 0xa94000 0x0 0x4000>;
				#address-cells = <1>;
				#size-cells = <0>;
				interrupts = <GIC_SPI 358 IRQ_TYPE_LEVEL_HIGH>;
				dmas = <&gpi_dma1 0 5 QCOM_GPI_I2C>,
				       <&gpi_dma1 1 5 QCOM_GPI_I2C>;
				dma-names = "tx",
					    "rx";
				status = "disabled";
			};

			spi12: spi@a94000 {
				compatible = "qcom,geni-spi";
				reg = <0x0 0xa94000 0x0 0x4000>;
				#address-cells = <1>;
				#size-cells = <0>;
				interrupts = <GIC_SPI 358 IRQ_TYPE_LEVEL_HIGH>;
				dmas = <&gpi_dma1 0 5 QCOM_GPI_SPI>,
				       <&gpi_dma1 1 5 QCOM_GPI_SPI>;
				dma-names = "tx",
					    "rx";
				status = "disabled";
			};

			uart12: serial@a94000 {
				compatible = "qcom,geni-uart";
				reg = <0x0 0x00a94000 0x0 0x4000>;
				interrupts = <GIC_SPI 358 IRQ_TYPE_LEVEL_HIGH>;
				status = "disabled";
			};

			i2c13: i2c@a98000 {
				compatible = "qcom,geni-i2c";
				reg = <0x0 0xa98000 0x0 0x4000>;
				#address-cells = <1>;
				#size-cells = <0>;
				interrupts = <GIC_SPI 835 IRQ_TYPE_LEVEL_HIGH>;
				dmas = <&gpi_dma1 0 6 QCOM_GPI_I2C>,
				       <&gpi_dma1 1 6 QCOM_GPI_I2C>;
				dma-names = "tx",
					    "rx";
				status = "disabled";

			};
		};

		gpi_dma3: dma-controller@b00000 {
			compatible = "qcom,sa8775p-gpi-dma", "qcom,sm6350-gpi-dma";
			reg = <0x0 0x00b00000 0x0 0x58000>;
			#dma-cells = <3>;
			interrupts = <GIC_SPI 368 IRQ_TYPE_LEVEL_HIGH>,
				     <GIC_SPI 369 IRQ_TYPE_LEVEL_HIGH>,
				     <GIC_SPI 527 IRQ_TYPE_LEVEL_HIGH>,
				     <GIC_SPI 528 IRQ_TYPE_LEVEL_HIGH>;
			iommus = <&apps_smmu 0x056 0x0>;
			dma-channels = <4>;
			dma-channel-mask = <0xf>;
			status = "disabled";
		};

		qupv3_id_3: geniqup@bc0000 {
			compatible = "qcom,geni-se-qup";
			reg = <0x0 0xbc0000 0x0 0x6000>;
			#address-cells = <2>;
			#size-cells = <2>;
			ranges;
			iommus = <&apps_smmu 0x43 0x0>;
			status = "disabled";

			i2c21: i2c@b80000 {
				compatible = "qcom,geni-i2c";
				reg = <0x0 0xb80000 0x0 0x4000>;
				#address-cells = <1>;
				#size-cells = <0>;
				interrupts = <GIC_SPI 831 IRQ_TYPE_LEVEL_HIGH>;
				dmas = <&gpi_dma3 0 0 QCOM_GPI_I2C>,
				       <&gpi_dma3 1 0 QCOM_GPI_I2C>;
				dma-names = "tx",
					    "rx";
				status = "disabled";
			};

			spi21: spi@b80000 {
				compatible = "qcom,geni-spi";
				reg = <0x0 0xb80000 0x0 0x4000>;
				#address-cells = <1>;
				#size-cells = <0>;
				interrupts = <GIC_SPI 831 IRQ_TYPE_LEVEL_HIGH>;
				dmas = <&gpi_dma3 0 0 QCOM_GPI_SPI>,
				       <&gpi_dma3 1 0 QCOM_GPI_SPI>;
				dma-names = "tx",
					    "rx";
				status = "disabled";
			};

			uart21: serial@b80000 {
				compatible = "qcom,geni-uart";
				reg = <0x0 0x00b80000 0x0 0x4000>;
				interrupts = <GIC_SPI 831 IRQ_TYPE_LEVEL_HIGH>;
				status = "disabled";
			};
		};

		rng: rng@10d2000 {
			compatible = "qcom,sa8775p-trng", "qcom,trng";
			reg = <0 0x010d2000 0 0x1000>;
		};

		pcie0: pcie@1c00000 {
			compatible = "qcom,pcie-sa8775p";
			reg = <0x0 0x01c00000 0x0 0x3000>,
			      <0x0 0x40000000 0x0 0xf20>,
			      <0x0 0x40000f20 0x0 0xa8>,
			      <0x0 0x40001000 0x0 0x4000>,
			      <0x0 0x40100000 0x0 0x100000>,
			      <0x0 0x01c03000 0x0 0x1000>;
			reg-names = "parf", "dbi", "elbi", "atu", "config", "mhi";
			device_type = "pci";

			#address-cells = <3>;
			#size-cells = <2>;
			ranges = <0x01000000 0x0 0x00000000 0x0 0x40200000 0x0 0x100000>,
				 <0x02000000 0x0 0x40300000 0x0 0x40300000 0x0 0x1fd00000>;
			bus-range = <0x00 0xff>;

			dma-coherent;

			num-lanes = <2>;

			interrupts = <GIC_SPI 307 IRQ_TYPE_LEVEL_HIGH>,
				     <GIC_SPI 308 IRQ_TYPE_LEVEL_HIGH>,
				     <GIC_SPI 309 IRQ_TYPE_LEVEL_HIGH>,
				     <GIC_SPI 312 IRQ_TYPE_LEVEL_HIGH>,
				     <GIC_SPI 313 IRQ_TYPE_LEVEL_HIGH>,
				     <GIC_SPI 314 IRQ_TYPE_LEVEL_HIGH>,
				     <GIC_SPI 374 IRQ_TYPE_LEVEL_HIGH>,
				     <GIC_SPI 375 IRQ_TYPE_LEVEL_HIGH>,
				     <GIC_SPI 306 IRQ_TYPE_LEVEL_HIGH>;
			interrupt-names = "msi0",
					  "msi1",
					  "msi2",
					  "msi3",
					  "msi4",
					  "msi5",
					  "msi6",
					  "msi7",
					  "global";
			#interrupt-cells = <1>;
			interrupt-map-mask = <0 0 0 0x7>;
			interrupt-map = <0 0 0 1 &intc GIC_SPI 434 IRQ_TYPE_LEVEL_HIGH>,
					<0 0 0 2 &intc GIC_SPI 435 IRQ_TYPE_LEVEL_HIGH>,
					<0 0 0 3 &intc GIC_SPI 438 IRQ_TYPE_LEVEL_HIGH>,
					<0 0 0 4 &intc GIC_SPI 439 IRQ_TYPE_LEVEL_HIGH>;

			iommu-map = <0x0 &pcie_smmu 0x0000 0x0 0x1>,
				    <0x100 &pcie_smmu 0x0001 0x0 0x1>;

			eq-presets-8gts = /bits/ 16 <0x5555 0x5555>;
			eq-presets-16gts = /bits/ 8 <0x55 0x55>;

			status = "disabled";

			pcieport0: pcie@0 {
				compatible = "pciclass,0604";
				device_type = "pci";
				reg = <0x0 0x0 0x0 0x0 0x0>;
				bus-range = <0x01 0xff>;

				#address-cells = <3>;
				#size-cells = <2>;
				ranges;
			};
		};

		pcie0_ep: pcie-ep@1c00000 {
			compatible = "qcom,sa8775p-pcie-ep";
			reg = <0x0 0x01c00000 0x0 0x3000>,
			      <0x0 0x40000000 0x0 0xf20>,
			      <0x0 0x40000f20 0x0 0xa8>,
			      <0x0 0x40001000 0x0 0x4000>,
			      <0x0 0x40200000 0x0 0x1fe00000>,
			      <0x0 0x01c03000 0x0 0x1000>,
			      <0x0 0x40005000 0x0 0x2000>;
			reg-names = "parf", "dbi", "elbi", "atu", "addr_space",
				    "mmio", "dma";
			interrupts = <GIC_SPI 306 IRQ_TYPE_LEVEL_HIGH>,
				     <GIC_SPI 147 IRQ_TYPE_LEVEL_HIGH>,
				     <GIC_SPI 630 IRQ_TYPE_LEVEL_HIGH>;

			interrupt-names = "global", "doorbell", "dma";

			dma-coherent;
			iommus = <&pcie_smmu 0x0000 0x7f>;
			num-lanes = <2>;

			status = "disabled";
		};

		pcie1: pcie@1c10000 {
			compatible = "qcom,pcie-sa8775p";
			reg = <0x0 0x01c10000 0x0 0x3000>,
			      <0x0 0x60000000 0x0 0xf20>,
			      <0x0 0x60000f20 0x0 0xa8>,
			      <0x0 0x60001000 0x0 0x4000>,
			      <0x0 0x60100000 0x0 0x100000>,
			      <0x0 0x01c13000 0x0 0x1000>;
			reg-names = "parf", "dbi", "elbi", "atu", "config", "mhi";
			device_type = "pci";

			#address-cells = <3>;
			#size-cells = <2>;
			ranges = <0x01000000 0x0 0x00000000 0x0 0x60200000 0x0 0x100000>,
				 <0x02000000 0x0 0x60300000 0x0 0x60300000 0x0 0x1fd00000>;
			bus-range = <0x00 0xff>;

			dma-coherent;

			num-lanes = <4>;

			interrupts = <GIC_SPI 519 IRQ_TYPE_LEVEL_HIGH>,
				     <GIC_SPI 140 IRQ_TYPE_LEVEL_HIGH>,
				     <GIC_SPI 141 IRQ_TYPE_LEVEL_HIGH>,
				     <GIC_SPI 142 IRQ_TYPE_LEVEL_HIGH>,
				     <GIC_SPI 143 IRQ_TYPE_LEVEL_HIGH>,
				     <GIC_SPI 144 IRQ_TYPE_LEVEL_HIGH>,
				     <GIC_SPI 145 IRQ_TYPE_LEVEL_HIGH>,
				     <GIC_SPI 146 IRQ_TYPE_LEVEL_HIGH>,
				     <GIC_SPI 518 IRQ_TYPE_LEVEL_HIGH>;
			interrupt-names = "msi0",
					  "msi1",
					  "msi2",
					  "msi3",
					  "msi4",
					  "msi5",
					  "msi6",
					  "msi7",
					  "global";
			#interrupt-cells = <1>;
			interrupt-map-mask = <0 0 0 0x7>;
			interrupt-map = <0 0 0 1 &intc GIC_SPI 148 IRQ_TYPE_LEVEL_HIGH>,
					<0 0 0 2 &intc GIC_SPI 149 IRQ_TYPE_LEVEL_HIGH>,
					<0 0 0 3 &intc GIC_SPI 150 IRQ_TYPE_LEVEL_HIGH>,
					<0 0 0 4 &intc GIC_SPI 151 IRQ_TYPE_LEVEL_HIGH>;

			iommu-map = <0x0 &pcie_smmu 0x0080 0x0 0x1>,
				    <0x100 &pcie_smmu 0x0081 0x0 0x1>;

			eq-presets-8gts = /bits/ 16 <0x5555 0x5555 0x5555 0x5555>;
			eq-presets-16gts = /bits/ 8 <0x55 0x55 0x55 0x55>;

			status = "disabled";

			pcie1_port0: pcie@0 {
				device_type = "pci";
				reg = <0x0 0x0 0x0 0x0 0x0>;
				bus-range = <0x01 0xff>;

				#address-cells = <3>;
				#size-cells = <2>;
				ranges;
			};
		};

		pcie1_ep: pcie-ep@1c10000 {
			compatible = "qcom,sa8775p-pcie-ep";
			reg = <0x0 0x01c10000 0x0 0x3000>,
			      <0x0 0x60000000 0x0 0xf20>,
			      <0x0 0x60000f20 0x0 0xa8>,
			      <0x0 0x60001000 0x0 0x4000>,
			      <0x0 0x60200000 0x0 0x1fe00000>,
			      <0x0 0x01c13000 0x0 0x1000>,
			      <0x0 0x60005000 0x0 0x2000>;
			reg-names = "parf", "dbi", "elbi", "atu", "addr_space",
				    "mmio", "dma";

			interrupts = <GIC_SPI 518 IRQ_TYPE_LEVEL_HIGH>,
				     <GIC_SPI 152 IRQ_TYPE_LEVEL_HIGH>,
				     <GIC_SPI 474 IRQ_TYPE_LEVEL_HIGH>;

			interrupt-names = "global", "doorbell", "dma";

			dma-coherent;
			iommus = <&pcie_smmu 0x80 0x7f>;
			num-lanes = <4>;

			status = "disabled";
		};

		ufs_mem_hc: ufshc@1d84000 {
			compatible = "qcom,sa8775p-ufshc", "qcom,ufshc", "jedec,ufs-2.0";
			reg = <0x0 0x01d84000 0x0 0x3000>;
			interrupts = <GIC_SPI 265 IRQ_TYPE_LEVEL_HIGH>;
			lanes-per-direction = <2>;
			iommus = <&apps_smmu 0x100 0x0>;
			dma-coherent;
			status = "disabled";
		};

		cryptobam: dma-controller@1dc4000 {
			compatible = "qcom,bam-v1.7.4", "qcom,bam-v1.7.0";
			reg = <0x0 0x01dc4000 0x0 0x28000>;
			interrupts = <GIC_SPI 272 IRQ_TYPE_LEVEL_HIGH>;
			#dma-cells = <1>;
			qcom,ee = <0>;
			qcom,num-ees = <4>;
			num-channels = <20>;
			qcom,controlled-remotely;
			iommus = <&apps_smmu 0x480 0x00>,
				 <&apps_smmu 0x481 0x00>;
		};

		crypto: crypto@1dfa000 {
			compatible = "qcom,sa8775p-qce", "qcom,sm8150-qce", "qcom,qce";
			reg = <0x0 0x01dfa000 0x0 0x6000>;
			dmas = <&cryptobam 4>, <&cryptobam 5>;
			dma-names = "rx", "tx";
			iommus = <&apps_smmu 0x480 0x0>,
				 <&apps_smmu 0x481 0x0>;
		};

		ctcu@4001000 {
			compatible = "qcom,sa8775p-ctcu";
			reg = <0x0 0x04001000 0x0 0x1000>;

			clocks = <&aoss_qmp>;
			clock-names = "apb";

			in-ports {
				#address-cells = <1>;
				#size-cells = <0>;

				port@0 {
					reg = <0>;

					ctcu_in0: endpoint {
						remote-endpoint = <&etr0_out>;
					};
				};

				port@1 {
					reg = <1>;

					ctcu_in1: endpoint {
						remote-endpoint = <&etr1_out>;
					};
				};
			};
		};

		stm: stm@4002000 {
			compatible = "arm,coresight-stm", "arm,primecell";
			reg = <0x0 0x4002000 0x0 0x1000>,
				  <0x0 0x16280000 0x0 0x180000>;
			reg-names = "stm-base", "stm-stimulus-base";

			clocks = <&aoss_qmp>;
			clock-names = "apb_pclk";

			out-ports {
				port {
					stm_out: endpoint {
						remote-endpoint =
						<&funnel0_in7>;
					};
				};
			};
		};

		tpdm@4003000 {
			compatible = "qcom,coresight-tpdm", "arm,primecell";
			reg = <0x0 0x4003000 0x0 0x1000>;

			clocks = <&aoss_qmp>;
			clock-names = "apb_pclk";
			label = "tpdm_dcc";

			qcom,cmb-element-bits = <32>;
			qcom,cmb-msrs-num = <32>;
			status = "disabled";

			out-ports {
				port {
					qdss_tpdm0_out: endpoint {
						remote-endpoint =
						<&qdss_tpda_in0>;
					};
				};
			};
		};

		tpda@4004000 {
			compatible = "qcom,coresight-tpda", "arm,primecell";
			reg = <0x0 0x4004000 0x0 0x1000>;

			clocks = <&aoss_qmp>;
			clock-names = "apb_pclk";

			out-ports {
				port {
					qdss_tpda_out: endpoint {
						remote-endpoint =
						<&funnel0_in6>;
					};
				};
			};

			in-ports {
				#address-cells = <1>;
				#size-cells = <0>;

				port@0 {
					reg = <0>;
					qdss_tpda_in0: endpoint {
						remote-endpoint =
						<&qdss_tpdm0_out>;
					};
				};

				port@1 {
					reg = <1>;
					qdss_tpda_in1: endpoint {
						remote-endpoint =
						<&qdss_tpdm1_out>;
					};
				};
			};
		};

		tpdm@400f000 {
			compatible = "qcom,coresight-tpdm", "arm,primecell";
			reg = <0x0 0x400f000 0x0 0x1000>;

			clocks = <&aoss_qmp>;
			clock-names = "apb_pclk";
			label = "tpdm_spdm";

			qcom,cmb-element-bits = <32>;
			qcom,cmb-msrs-num = <32>;

			out-ports {
				port {
					qdss_tpdm1_out: endpoint {
						remote-endpoint =
						<&qdss_tpda_in1>;
					};
				};
			};
		};

		funnel@4041000 {
			compatible = "arm,coresight-dynamic-funnel", "arm,primecell";
			reg = <0x0 0x4041000 0x0 0x1000>;

			clocks = <&aoss_qmp>;
			clock-names = "apb_pclk";

			out-ports {
				port {
					funnel0_out: endpoint {
						remote-endpoint =
						<&qdss_funnel_in0>;
					};
				};
			};

			in-ports {
				#address-cells = <1>;
				#size-cells = <0>;

				port@6 {
					reg = <6>;
					funnel0_in6: endpoint {
						remote-endpoint =
						<&qdss_tpda_out>;
					};
				};

				port@7 {
					reg = <7>;
					funnel0_in7: endpoint {
						remote-endpoint =
						<&stm_out>;
					};
				};
			};
		};

		funnel@4042000 {
			compatible = "arm,coresight-dynamic-funnel", "arm,primecell";
			reg = <0x0 0x4042000 0x0 0x1000>;

			clocks = <&aoss_qmp>;
			clock-names = "apb_pclk";

			out-ports {
				port {
					funnel1_out: endpoint {
						remote-endpoint =
						<&qdss_funnel_in1>;
					};
				};
			};

			in-ports {
				#address-cells = <1>;
				#size-cells = <0>;

				port@4 {
					reg = <4>;
					funnel1_in4: endpoint {
						remote-endpoint =
						<&apss_funnel1_out>;
					};
				};

				port@5 {
					reg = <5>;

					funnel1_in5: endpoint {
						remote-endpoint = <&dlct0_funnel_out>;
					};
				};
			};
		};

		funnel@4045000 {
			compatible = "arm,coresight-dynamic-funnel", "arm,primecell";
			reg = <0x0 0x4045000 0x0 0x1000>;

			clocks = <&aoss_qmp>;
			clock-names = "apb_pclk";

			out-ports {
				port {
					qdss_funnel_out: endpoint {
						remote-endpoint =
						<&aoss_funnel_in7>;
					};
				};
			};

			in-ports {
				#address-cells = <1>;
				#size-cells = <0>;

				port@0 {
					reg = <0>;
					qdss_funnel_in0: endpoint {
						remote-endpoint =
						<&funnel0_out>;
					};
				};

				port@1 {
					reg = <1>;
					qdss_funnel_in1: endpoint {
						remote-endpoint =
						<&funnel1_out>;
					};
				};
			};
		};

		replicator@4046000 {
			compatible = "arm,coresight-dynamic-replicator", "arm,primecell";
			reg = <0x0 0x04046000 0x0 0x1000>;

			clocks = <&aoss_qmp>;
			clock-names = "apb_pclk";

			in-ports {
				port {
					qdss_rep_in: endpoint {
						remote-endpoint = <&swao_rep_out0>;
					};
				};
			};

			out-ports {
				port {
					qdss_rep_out0: endpoint {
						remote-endpoint = <&etr_rep_in>;
					};
				};
			};
		};

		tmc_etr: tmc@4048000 {
			compatible = "arm,coresight-tmc", "arm,primecell";
			reg = <0x0 0x04048000 0x0 0x1000>;

			clocks = <&aoss_qmp>;
			clock-names = "apb_pclk";
			iommus = <&apps_smmu 0x04c0 0x00>;

			arm,scatter-gather;

			in-ports {
				port {
					etr0_in: endpoint {
						remote-endpoint = <&etr_rep_out0>;
					};
				};
			};

			out-ports {
				port {
					etr0_out: endpoint {
						remote-endpoint = <&ctcu_in0>;
					};
				};
			};
		};

		replicator@404e000 {
			compatible = "arm,coresight-dynamic-replicator", "arm,primecell";
			reg = <0x0 0x0404e000 0x0 0x1000>;

			clocks = <&aoss_qmp>;
			clock-names = "apb_pclk";

			in-ports {
				port {
					etr_rep_in: endpoint {
						remote-endpoint = <&qdss_rep_out0>;
					};
				};
			};

			out-ports {
				#address-cells = <1>;
				#size-cells = <0>;

				port@0 {
					reg = <0>;

					etr_rep_out0: endpoint {
						remote-endpoint = <&etr0_in>;
					};
				};

				port@1 {
					reg = <1>;

					etr_rep_out1: endpoint {
						remote-endpoint = <&etr1_in>;
					};
				};
			};
		};

		tmc_etr1: tmc@404f000 {
			compatible = "arm,coresight-tmc", "arm,primecell";
			reg = <0x0 0x0404f000 0x0 0x1000>;

			clocks = <&aoss_qmp>;
			clock-names = "apb_pclk";
			iommus = <&apps_smmu 0x04a0 0x40>;

			arm,scatter-gather;
			arm,buffer-size = <0x400000>;

			in-ports {
				port {
					etr1_in: endpoint {
						remote-endpoint = <&etr_rep_out1>;
					};
				};
			};

			out-ports {
				port {
					etr1_out: endpoint {
						remote-endpoint = <&ctcu_in1>;
					};
				};
			};
		};

		tpda@4ad3000 {
			compatible = "qcom,coresight-tpda", "arm,primecell";
			reg = <0x0 0x4ad3000 0x0 0x1000>;

			clocks = <&aoss_qmp>;
			clock-names = "apb_pclk";

			in-ports {
				#address-cells = <1>;
				#size-cells = <0>;

				port@10 {
					reg = <16>;
					dlct0_tpda_in16: endpoint {
						remote-endpoint = <&turing0_funnel_out>;
					};
				};
			};

			out-ports {
				port {
					dlct0_tpda_out: endpoint {
						remote-endpoint =
						<&dlct0_funnel_in0>;
					};
				};
			};

		};

		funnel@4ad4000 {
			compatible = "arm,coresight-dynamic-funnel", "arm,primecell";
			reg = <0x0 0x4ad4000 0x0 0x1000>;

			clocks = <&aoss_qmp>;
			clock-names = "apb_pclk";

			in-ports {
				port {
					dlct0_funnel_in0: endpoint {
						remote-endpoint = <&dlct0_tpda_out>;
					};
				};
			};

			out-ports {
				port {
					dlct0_funnel_out: endpoint {
						remote-endpoint = <&funnel1_in5>;
					};
				};
			};
		};

		funnel@4b04000 {
			compatible = "arm,coresight-dynamic-funnel", "arm,primecell";
			reg = <0x0 0x4b04000 0x0 0x1000>;

			clocks = <&aoss_qmp>;
			clock-names = "apb_pclk";

			out-ports {
				port {
					aoss_funnel_out: endpoint {
						remote-endpoint =
						<&etf0_in>;
					};
				};
			};

			in-ports {
				#address-cells = <1>;
				#size-cells = <0>;

				port@6 {
					reg = <6>;
					aoss_funnel_in6: endpoint {
						remote-endpoint =
						<&aoss_tpda_out>;
					};
				};

				port@7 {
					reg = <7>;
					aoss_funnel_in7: endpoint {
						remote-endpoint =
						<&qdss_funnel_out>;
					};
				};
			};
		};

		tmc_etf: tmc@4b05000 {
			compatible = "arm,coresight-tmc", "arm,primecell";
			reg = <0x0 0x4b05000 0x0 0x1000>;

			clocks = <&aoss_qmp>;
			clock-names = "apb_pclk";

			out-ports {
				port {
					etf0_out: endpoint {
						remote-endpoint =
						<&swao_rep_in>;
					};
				};
			};

			in-ports {
				port {
					etf0_in: endpoint {
						remote-endpoint =
						<&aoss_funnel_out>;
					};
				};
			};
		};

		replicator@4b06000 {
			compatible = "arm,coresight-dynamic-replicator", "arm,primecell";
			reg = <0x0 0x4b06000 0x0 0x1000>;

			clocks = <&aoss_qmp>;
			clock-names = "apb_pclk";

			out-ports {
				#address-cells = <1>;
				#size-cells = <0>;

				port@0 {
					reg = <0>;

					swao_rep_out0: endpoint {
						remote-endpoint = <&qdss_rep_in>;
					};
				};

				port@1 {
					reg = <1>;
					swao_rep_out1: endpoint {
						remote-endpoint =
						<&eud_in>;
					};
				};
			};

			in-ports {
				port {
					swao_rep_in: endpoint {
						remote-endpoint =
						<&etf0_out>;
					};
				};
			};
		};

		tpda@4b08000 {
			compatible = "qcom,coresight-tpda", "arm,primecell";
			reg = <0x0 0x4b08000 0x0 0x1000>;

			clocks = <&aoss_qmp>;
			clock-names = "apb_pclk";

			out-ports {
				port {
					aoss_tpda_out: endpoint {
						remote-endpoint =
						<&aoss_funnel_in6>;
					};
				};
			};

			in-ports {
				#address-cells = <1>;
				#size-cells = <0>;

				port@0 {
					reg = <0>;
					aoss_tpda_in0: endpoint {
						remote-endpoint =
						<&aoss_tpdm0_out>;
					};
				};

				port@1 {
					reg = <1>;
					aoss_tpda_in1: endpoint {
						remote-endpoint =
						<&aoss_tpdm1_out>;
					};
				};

				port@2 {
					reg = <2>;
					aoss_tpda_in2: endpoint {
						remote-endpoint =
						<&aoss_tpdm2_out>;
					};
				};

				port@3 {
					reg = <3>;
					aoss_tpda_in3: endpoint {
						remote-endpoint =
						<&aoss_tpdm3_out>;
					};
				};

				port@4 {
					reg = <4>;
					aoss_tpda_in4: endpoint {
						remote-endpoint =
						<&aoss_tpdm4_out>;
					};
				};
			};
		};

		tpdm@4b09000 {
			compatible = "qcom,coresight-tpdm", "arm,primecell";
			reg = <0x0 0x4b09000 0x0 0x1000>;

			clocks = <&aoss_qmp>;
			clock-names = "apb_pclk";
			label = "tpdm_swao_prio_0";

			qcom,cmb-element-bits = <64>;
			qcom,cmb-msrs-num = <32>;

			out-ports {
				port {
					aoss_tpdm0_out: endpoint {
						remote-endpoint =
						<&aoss_tpda_in0>;
					};
				};
			};
		};

		tpdm@4b0a000 {
			compatible = "qcom,coresight-tpdm", "arm,primecell";
			reg = <0x0 0x4b0a000 0x0 0x1000>;

			clocks = <&aoss_qmp>;
			clock-names = "apb_pclk";
			label = "tpdm_swao_prio_1";

			qcom,cmb-element-bits = <64>;
			qcom,cmb-msrs-num = <32>;

			out-ports {
				port {
					aoss_tpdm1_out: endpoint {
						remote-endpoint =
						<&aoss_tpda_in1>;
					};
				};
			};
		};

		tpdm@4b0b000 {
			compatible = "qcom,coresight-tpdm", "arm,primecell";
			reg = <0x0 0x4b0b000 0x0 0x1000>;

			clocks = <&aoss_qmp>;
			clock-names = "apb_pclk";
			label = "tpdm_swao_prio_2";

			qcom,cmb-element-bits = <64>;
			qcom,cmb-msrs-num = <32>;

			out-ports {
				port {
					aoss_tpdm2_out: endpoint {
						remote-endpoint =
						<&aoss_tpda_in2>;
					};
				};
			};
		};

		tpdm@4b0c000 {
			compatible = "qcom,coresight-tpdm", "arm,primecell";
			reg = <0x0 0x4b0c000 0x0 0x1000>;

			clocks = <&aoss_qmp>;
			clock-names = "apb_pclk";
			label = "tpdm_swao_prio_3";

			qcom,cmb-element-bits = <64>;
			qcom,cmb-msrs-num = <32>;

			out-ports {
				port {
					aoss_tpdm3_out: endpoint {
						remote-endpoint =
						<&aoss_tpda_in3>;
					};
				};
			};
		};

		tpdm@4b0d000 {
			compatible = "qcom,coresight-tpdm", "arm,primecell";
			reg = <0x0 0x4b0d000 0x0 0x1000>;

			clocks = <&aoss_qmp>;
			clock-names = "apb_pclk";
			label = "tpdm_swao_1";

			qcom,dsb-element-bits = <32>;
			qcom,dsb-msrs-num = <32>;

			out-ports {
				port {
					aoss_tpdm4_out: endpoint {
						remote-endpoint =
						<&aoss_tpda_in4>;
					};
				};
			};
		};

		aoss_cti: cti@4b13000 {
			compatible = "arm,coresight-cti", "arm,primecell";
			reg = <0x0 0x4b13000 0x0 0x1000>;

			clocks = <&aoss_qmp>;
			clock-names = "apb_pclk";
			label = "cti_aoss";
		};

		funnel@4b83000 {
			compatible = "arm,coresight-dynamic-funnel", "arm,primecell";
			reg = <0x0 0x4b83000 0x0 0x1000>;

			clocks = <&aoss_qmp>;
			clock-names = "apb_pclk";

			in-ports {
				#address-cells = <1>;
				#size-cells = <0>;

				port@1 {
					reg = <1>;

					turing0_funnel_in1: endpoint {
						remote-endpoint = <&turing_llm_tpdm_out>;
					};
				};
			};

			out-ports {
				port {
					turing0_funnel_out: endpoint {
						remote-endpoint = <&dlct0_tpda_in16>;
					};
				};
			};
		};

		etm@6040000 {
			compatible = "arm,primecell";
			reg = <0x0 0x6040000 0x0 0x1000>;
			cpu = <&cpu0>;

			clocks = <&aoss_qmp>;
			clock-names = "apb_pclk";
			arm,coresight-loses-context-with-cpu;
			qcom,skip-power-up;

			out-ports {
				port {
					etm0_out: endpoint {
						remote-endpoint =
						<&apss_funnel0_in0>;
					};
				};
			};
		};

		etm@6140000 {
			compatible = "arm,primecell";
			reg = <0x0 0x6140000 0x0 0x1000>;
			cpu = <&cpu1>;

			clocks = <&aoss_qmp>;
			clock-names = "apb_pclk";
			arm,coresight-loses-context-with-cpu;
			qcom,skip-power-up;

			out-ports {
				port {
					etm1_out: endpoint {
						remote-endpoint =
						<&apss_funnel0_in1>;
					};
				};
			};
		};

		etm@6240000 {
			compatible = "arm,primecell";
			reg = <0x0 0x6240000 0x0 0x1000>;
			cpu = <&cpu2>;

			clocks = <&aoss_qmp>;
			clock-names = "apb_pclk";
			arm,coresight-loses-context-with-cpu;
			qcom,skip-power-up;

			out-ports {
				port {
					etm2_out: endpoint {
						remote-endpoint =
						<&apss_funnel0_in2>;
					};
				};
			};
		};

		etm@6340000 {
			compatible = "arm,primecell";
			reg = <0x0 0x6340000 0x0 0x1000>;
			cpu = <&cpu3>;

			clocks = <&aoss_qmp>;
			clock-names = "apb_pclk";
			arm,coresight-loses-context-with-cpu;
			qcom,skip-power-up;

			out-ports {
				port {
					etm3_out: endpoint {
						remote-endpoint =
						<&apss_funnel0_in3>;
					};
				};
			};
		};

		etm@6440000 {
			compatible = "arm,primecell";
			reg = <0x0 0x6440000 0x0 0x1000>;
			cpu = <&cpu4>;

			clocks = <&aoss_qmp>;
			clock-names = "apb_pclk";
			arm,coresight-loses-context-with-cpu;
			qcom,skip-power-up;

			out-ports {
				port {
					etm4_out: endpoint {
						remote-endpoint =
						<&apss_funnel0_in4>;
					};
				};
			};
		};

		etm@6540000 {
			compatible = "arm,primecell";
			reg = <0x0 0x6540000 0x0 0x1000>;
			cpu = <&cpu5>;

			clocks = <&aoss_qmp>;
			clock-names = "apb_pclk";
			arm,coresight-loses-context-with-cpu;
			qcom,skip-power-up;

			out-ports {
				port {
					etm5_out: endpoint {
						remote-endpoint =
						<&apss_funnel0_in5>;
					};
				};
			};
		};

		etm@6640000 {
			compatible = "arm,primecell";
			reg = <0x0 0x6640000 0x0 0x1000>;
			cpu = <&cpu6>;

			clocks = <&aoss_qmp>;
			clock-names = "apb_pclk";
			arm,coresight-loses-context-with-cpu;
			qcom,skip-power-up;

			out-ports {
				port {
					etm6_out: endpoint {
						remote-endpoint =
						<&apss_funnel0_in6>;
					};
				};
			};
		};

		etm@6740000 {
			compatible = "arm,primecell";
			reg = <0x0 0x6740000 0x0 0x1000>;
			cpu = <&cpu7>;

			clocks = <&aoss_qmp>;
			clock-names = "apb_pclk";
			arm,coresight-loses-context-with-cpu;
			qcom,skip-power-up;

			out-ports {
				port {
					etm7_out: endpoint {
						remote-endpoint =
						<&apss_funnel0_in7>;
					};
				};
			};
		};

		funnel@6800000 {
			compatible = "arm,coresight-dynamic-funnel", "arm,primecell";
			reg = <0x0 0x6800000 0x0 0x1000>;

			clocks = <&aoss_qmp>;
			clock-names = "apb_pclk";

			out-ports {
				port {
					apss_funnel0_out: endpoint {
						remote-endpoint =
						<&apss_funnel1_in0>;
					};
				};
			};

			in-ports {
				#address-cells = <1>;
				#size-cells = <0>;

				port@0 {
					reg = <0>;
					apss_funnel0_in0: endpoint {
						remote-endpoint =
						<&etm0_out>;
					};
				};

				port@1 {
					reg = <1>;
					apss_funnel0_in1: endpoint {
						remote-endpoint =
						<&etm1_out>;
					};
				};

				port@2 {
					reg = <2>;
					apss_funnel0_in2: endpoint {
						remote-endpoint =
						<&etm2_out>;
					};
				};

				port@3 {
					reg = <3>;
					apss_funnel0_in3: endpoint {
						remote-endpoint =
						<&etm3_out>;
					};
				};

				port@4 {
					reg = <4>;
					apss_funnel0_in4: endpoint {
						remote-endpoint =
						<&etm4_out>;
					};
				};

				port@5 {
					reg = <5>;
					apss_funnel0_in5: endpoint {
						remote-endpoint =
						<&etm5_out>;
					};
				};

				port@6 {
					reg = <6>;
					apss_funnel0_in6: endpoint {
						remote-endpoint =
						<&etm6_out>;
					};
				};

				port@7 {
					reg = <7>;
					apss_funnel0_in7: endpoint {
						remote-endpoint =
						<&etm7_out>;
					};
				};
			};
		};

		funnel@6810000 {
			compatible = "arm,coresight-dynamic-funnel", "arm,primecell";
			reg = <0x0 0x6810000 0x0 0x1000>;

			clocks = <&aoss_qmp>;
			clock-names = "apb_pclk";

			out-ports {
				port {
					apss_funnel1_out: endpoint {
						remote-endpoint =
						<&funnel1_in4>;
					};
				};
			};

			in-ports {
				#address-cells = <1>;
				#size-cells = <0>;

				port@0 {
					reg = <0>;
					apss_funnel1_in0: endpoint {
						remote-endpoint =
						<&apss_funnel0_out>;
					};
				};

				port@3 {
					reg = <3>;
					apss_funnel1_in3: endpoint {
						remote-endpoint =
						<&apss_tpda_out>;
					};
				};
			};
		};

		tpdm@6860000 {
			compatible = "qcom,coresight-tpdm", "arm,primecell";
			reg = <0x0 0x6860000 0x0 0x1000>;

			clocks = <&aoss_qmp>;
			clock-names = "apb_pclk";
			label = "tpdm_actpm";

			qcom,cmb-element-bits = <64>;
			qcom,cmb-msrs-num = <32>;

			out-ports {
				port {
					apss_tpdm3_out: endpoint {
						remote-endpoint =
						<&apss_tpda_in3>;
					};
				};
			};
		};

		tpdm@6861000 {
			compatible = "qcom,coresight-tpdm", "arm,primecell";
			reg = <0x0 0x6861000 0x0 0x1000>;

			clocks = <&aoss_qmp>;
			clock-names = "apb_pclk";
			label = "tpdm_apss";

			qcom,dsb-element-bits = <32>;
			qcom,dsb-msrs-num = <32>;

			out-ports {
				port {
					apss_tpdm4_out: endpoint {
						remote-endpoint =
						<&apss_tpda_in4>;
					};
				};
			};
		};

		tpda@6863000 {
			compatible = "qcom,coresight-tpda", "arm,primecell";
			reg = <0x0 0x6863000 0x0 0x1000>;

			clocks = <&aoss_qmp>;
			clock-names = "apb_pclk";

			out-ports {
				port {
					apss_tpda_out: endpoint {
						remote-endpoint =
						<&apss_funnel1_in3>;
					};
				};
			};

			in-ports {
				#address-cells = <1>;
				#size-cells = <0>;

				port@0 {
					reg = <0>;
					apss_tpda_in0: endpoint {
						remote-endpoint =
						<&apss_tpdm0_out>;
					};
				};

				port@1 {
					reg = <1>;
					apss_tpda_in1: endpoint {
						remote-endpoint =
						<&apss_tpdm1_out>;
					};
				};

				port@2 {
					reg = <2>;
					apss_tpda_in2: endpoint {
						remote-endpoint =
						<&apss_tpdm2_out>;
					};
				};

				port@3 {
					reg = <3>;
					apss_tpda_in3: endpoint {
						remote-endpoint =
						<&apss_tpdm3_out>;
					};
				};

				port@4 {
					reg = <4>;
					apss_tpda_in4: endpoint {
						remote-endpoint =
						<&apss_tpdm4_out>;
					};
				};
			};
		};

		tpdm@68a0000 {
			compatible = "qcom,coresight-tpdm", "arm,primecell";
			reg = <0x0 0x68a0000 0x0 0x1000>;

			clocks = <&aoss_qmp>;
			clock-names = "apb_pclk";
			label = "tpdm_llm_silver";

			qcom,cmb-element-bits = <32>;
			qcom,cmb-msrs-num = <32>;

			out-ports {
				port {
					apss_tpdm0_out: endpoint {
						remote-endpoint =
						<&apss_tpda_in0>;
					};
				};
			};
		};

		tpdm@68b0000 {
			compatible = "qcom,coresight-tpdm", "arm,primecell";
			reg = <0x0 0x68b0000 0x0 0x1000>;

			clocks = <&aoss_qmp>;
			clock-names = "apb_pclk";
			label = "tpdm_llm_gold";

			qcom,cmb-element-bits = <32>;
			qcom,cmb-msrs-num = <32>;

			out-ports {
				port {
					apss_tpdm1_out: endpoint {
						remote-endpoint =
						<&apss_tpda_in1>;
					};
				};
			};
		};

		tpdm@68c0000 {
			compatible = "qcom,coresight-tpdm", "arm,primecell";
			reg = <0x0 0x68c0000 0x0 0x1000>;

			clocks = <&aoss_qmp>;
			clock-names = "apb_pclk";
			label = "tpdm_llm_ext";

			qcom,dsb-element-bits = <32>;
			qcom,dsb-msrs-num = <32>;

			out-ports {
				port {
					apss_tpdm2_out: endpoint {
						remote-endpoint =
						<&apss_tpda_in2>;
					};
				};
			};
		};

		sdhc: mmc@87c4000 {
			compatible = "qcom,sa8775p-sdhci", "qcom,sdhci-msm-v5";
			reg = <0x0 0x087c4000 0x0 0x1000>;

			interrupts = <GIC_SPI 383 IRQ_TYPE_LEVEL_HIGH>,
				     <GIC_SPI 521 IRQ_TYPE_LEVEL_HIGH>;
			interrupt-names = "hc_irq",
					  "pwr_irq";

			iommus = <&apps_smmu 0x0 0x0>;
			dma-coherent;

			qcom,dll-config = <0x0007642c>;
			qcom,ddr-config = <0x80040868>;

			status = "disabled";
		};

		usb_0: usb@a600000 {
			compatible = "qcom,sa8775p-dwc3", "qcom,snps-dwc3";
			reg = <0 0x0a600000 0 0xfc100>;

			interrupts-extended = <&intc GIC_SPI 292 IRQ_TYPE_LEVEL_HIGH>,
					      <&intc GIC_SPI 287 IRQ_TYPE_LEVEL_HIGH>,
					      <&intc GIC_SPI 261 IRQ_TYPE_LEVEL_HIGH>,
					      <&pdc 14 IRQ_TYPE_EDGE_BOTH>,
					      <&pdc 15 IRQ_TYPE_EDGE_BOTH>,
					      <&pdc 12 IRQ_TYPE_LEVEL_HIGH>;
			interrupt-names = "dwc_usb3",
					  "pwr_event",
					  "hs_phy_irq",
					  "dp_hs_phy_irq",
					  "dm_hs_phy_irq",
					  "ss_phy_irq";

			wakeup-source;

			iommus = <&apps_smmu 0x080 0x0>;
			snps,dis-u1-entry-quirk;
			snps,dis-u2-entry-quirk;

			usb-role-switch;
			dma-coherent;

			status = "disabled";

			ports {
				#address-cells = <1>;
				#size-cells = <0>;

				port@0 {
					reg = <0>;

					usb_0_dwc3_hs: endpoint {
					};
				};

				port@1 {
					reg = <1>;

					usb_0_dwc3_ss: endpoint {
					};
				};
			};
		};

		usb_1: usb@a800000 {
			compatible = "qcom,sa8775p-dwc3", "qcom,snps-dwc3";
			reg = <0 0x0a800000 0 0xfc100>;

			interrupts-extended = <&intc GIC_SPI 349 IRQ_TYPE_LEVEL_HIGH>,
					      <&intc GIC_SPI 352 IRQ_TYPE_LEVEL_HIGH>,
					      <&intc GIC_SPI 351 IRQ_TYPE_LEVEL_HIGH>,
					      <&pdc 8 IRQ_TYPE_EDGE_BOTH>,
					      <&pdc 7 IRQ_TYPE_EDGE_BOTH>,
					      <&pdc 13 IRQ_TYPE_LEVEL_HIGH>;
			interrupt-names = "dwc_usb3",
					  "pwr_event",
					  "hs_phy_irq",
					  "dp_hs_phy_irq",
					  "dm_hs_phy_irq",
					  "ss_phy_irq";

			wakeup-source;

			iommus = <&apps_smmu 0x0a0 0x0>;
			snps,dis-u1-entry-quirk;
			snps,dis-u2-entry-quirk;

			dma-coherent;

			status = "disabled";
		};

		usb_2: usb@a400000 {
			compatible = "qcom,sa8775p-dwc3", "qcom,snps-dwc3";
			reg = <0 0x0a400000 0 0xfc100>;

			interrupts-extended = <&intc GIC_SPI 442 IRQ_TYPE_LEVEL_HIGH>,
					      <&intc GIC_SPI 444 IRQ_TYPE_LEVEL_HIGH>,
					      <&intc GIC_SPI 443 IRQ_TYPE_LEVEL_HIGH>,
					      <&pdc 10 IRQ_TYPE_EDGE_BOTH>,
					      <&pdc 9 IRQ_TYPE_EDGE_BOTH>;
			interrupt-names = "dwc_usb3",
					  "pwr_event",
					  "hs_phy_irq",
					  "dp_hs_phy_irq",
					  "dm_hs_phy_irq";

			qcom,select-utmi-as-pipe-clk;
			wakeup-source;

			iommus = <&apps_smmu 0x020 0x0>;
			snps,dis-u1-entry-quirk;
			snps,dis-u2-entry-quirk;

			usb-role-switch;
			dma-coherent;

			status = "disabled";

			port {
				usb_2_dwc3_hs: endpoint {
				};
			};
		};

		tcsr_mutex: hwlock@1f40000 {
			compatible = "qcom,tcsr-mutex";
			reg = <0x0 0x01f40000 0x0 0x20000>;
			#hwlock-cells = <1>;
		};

		tcsr: syscon@1fc0000 {
			compatible = "qcom,sa8775p-tcsr", "syscon";
			reg = <0x0 0x1fc0000 0x0 0x30000>;
		};

		gpu: gpu@3d00000 {
			compatible = "qcom,adreno-663.0", "qcom,adreno";
			reg = <0x0 0x03d00000 0x0 0x40000>,
			      <0x0 0x03d9e000 0x0 0x1000>,
			      <0x0 0x03d61000 0x0 0x800>;
			reg-names = "kgsl_3d0_reg_memory",
				    "cx_mem",
				    "cx_dbgc";
			interrupts = <GIC_SPI 300 IRQ_TYPE_LEVEL_HIGH>;
			iommus = <&adreno_smmu 0 0xc00>,
				 <&adreno_smmu 1 0xc00>;
			qcom,gmu = <&gmu>;
			#cooling-cells = <2>;

			nvmem-cells = <&gpu_speed_bin>;
			nvmem-cell-names = "speed_bin";

			status = "disabled";

			gpu_zap_shader: zap-shader {
				memory-region = <&pil_gpu_mem>;
			};
		};

		gmu: gmu@3d6a000 {
			reg = <0x0 0x03d6a000 0x0 0x34000>,
			      <0x0 0x03de0000 0x0 0x10000>,
			      <0x0 0x0b290000 0x0 0x10000>;
			reg-names = "gmu", "rscc", "gmu_pdc";
			interrupts = <GIC_SPI 304 IRQ_TYPE_LEVEL_HIGH>,
				     <GIC_SPI 305 IRQ_TYPE_LEVEL_HIGH>;
			interrupt-names = "hfi", "gmu";
			iommus = <&adreno_smmu 5 0xc00>;
		};

		adreno_smmu: iommu@3da0000 {
			compatible = "qcom,sa8775p-smmu-500", "qcom,adreno-smmu",
				     "qcom,smmu-500", "arm,mmu-500";
			reg = <0x0 0x03da0000 0x0 0x20000>;
			#iommu-cells = <2>;
			#global-interrupts = <2>;
			dma-coherent;
			interrupts = <GIC_SPI 673 IRQ_TYPE_LEVEL_HIGH>,
				     <GIC_SPI 674 IRQ_TYPE_LEVEL_HIGH>,
				     <GIC_SPI 678 IRQ_TYPE_LEVEL_HIGH>,
				     <GIC_SPI 679 IRQ_TYPE_LEVEL_HIGH>,
				     <GIC_SPI 680 IRQ_TYPE_LEVEL_HIGH>,
				     <GIC_SPI 681 IRQ_TYPE_LEVEL_HIGH>,
				     <GIC_SPI 682 IRQ_TYPE_LEVEL_HIGH>,
				     <GIC_SPI 683 IRQ_TYPE_LEVEL_HIGH>,
				     <GIC_SPI 684 IRQ_TYPE_LEVEL_HIGH>,
				     <GIC_SPI 685 IRQ_TYPE_LEVEL_HIGH>,
				     <GIC_SPI 686 IRQ_TYPE_LEVEL_HIGH>,
				     <GIC_SPI 687 IRQ_TYPE_LEVEL_HIGH>;
		};

		llcc_bwmon: pmu@9091000 {
			reg = <0x0 0x9091000 0x0 0x1000>;
			interrupts = <GIC_SPI 620 IRQ_TYPE_LEVEL_HIGH>;

			operating-points-v2 = <&llcc_bwmon_opp_table>;

			llcc_bwmon_opp_table: opp-table {
				compatible = "operating-points-v2";

				opp-0 {
					opp-peak-kBps = <762000>;
				};

				opp-1 {
					opp-peak-kBps = <1720000>;
				};

				opp-2 {
					opp-peak-kBps = <2086000>;
				};

				opp-3 {
					opp-peak-kBps = <2601000>;
				};

				opp-4 {
					opp-peak-kBps = <2929000>;
				};

				opp-5 {
					opp-peak-kBps = <5931000>;
				};

				opp-6 {
					opp-peak-kBps = <6515000>;
				};

				opp-7 {
					opp-peak-kBps = <7984000>;
				};

				opp-8 {
					opp-peak-kBps = <10437000>;
				};

				opp-9 {
					opp-peak-kBps = <12195000>;
				};
			};
		};

		cpu_bwmon0: pmu@90b5400 {
			reg = <0x0 0x90b5400 0x0 0x600>;
			interrupts = <GIC_SPI 581 IRQ_TYPE_LEVEL_HIGH>;

			operating-points-v2 = <&cpu_bwmon_opp_table>;

			cpu_bwmon_opp_table: opp-table {
				compatible = "operating-points-v2";

				opp-0 {
					opp-peak-kBps = <9155000>;
				};

				opp-1 {
					opp-peak-kBps = <12298000>;
				};

				opp-2 {
					opp-peak-kBps = <14236000>;
				};

				opp-3 {
					opp-peak-kBps = <16265000>;
				};
			};
		};

		cpu_bwmon1: pmu@90b6400 {
			reg = <0x0 0x90b6400 0x0 0x600>;
			interrupts = <GIC_SPI 581 IRQ_TYPE_LEVEL_HIGH>;

			operating-points-v2 = <&cpu_bwmon_opp_table>;
		};

		llcc: system-cache-controller@9200000 {
			compatible = "qcom,sa8775p-llcc";
			reg = <0x0 0x09200000 0x0 0x80000>,
			      <0x0 0x09300000 0x0 0x80000>,
			      <0x0 0x09400000 0x0 0x80000>,
			      <0x0 0x09500000 0x0 0x80000>,
			      <0x0 0x09600000 0x0 0x80000>,
			      <0x0 0x09700000 0x0 0x80000>,
			      <0x0 0x09a00000 0x0 0x80000>;
			reg-names = "llcc0_base",
				    "llcc1_base",
				    "llcc2_base",
				    "llcc3_base",
				    "llcc4_base",
				    "llcc5_base",
				    "llcc_broadcast_base";
			interrupts = <GIC_SPI 580 IRQ_TYPE_LEVEL_HIGH>;
		};

		iris: video-codec@aa00000 {
			compatible = "qcom,sa8775p-iris", "qcom,sm8550-iris";

			reg = <0x0 0x0aa00000 0x0 0xf0000>;
			interrupts = <GIC_SPI 174 IRQ_TYPE_LEVEL_HIGH>;

			memory-region = <&pil_video_mem>;

			iommus = <&apps_smmu 0x0880 0x0400>,
				 <&apps_smmu 0x0887 0x0400>;
			dma-coherent;

			status = "disabled";
		};

		cci0: cci@ac13000 {
			compatible = "qcom,sa8775p-cci", "qcom,msm8996-cci";
			reg = <0x0 0x0ac13000 0x0 0x1000>;
			interrupts = <GIC_SPI 460 IRQ_TYPE_EDGE_RISING>;

			#address-cells = <1>;
			#size-cells = <0>;

			status = "disabled";

			cci0_i2c0: i2c-bus@0 {
				reg = <0>;
				clock-frequency = <1000000>;
				#address-cells = <1>;
				#size-cells = <0>;
			};

			cci0_i2c1: i2c-bus@1 {
				reg = <1>;
				clock-frequency = <1000000>;
				#address-cells = <1>;
				#size-cells = <0>;
			};
		};

		cci1: cci@ac14000 {
			compatible = "qcom,sa8775p-cci", "qcom,msm8996-cci";
			reg = <0x0 0x0ac14000 0x0 0x1000>;
			interrupts = <GIC_SPI 271 IRQ_TYPE_EDGE_RISING>;

			#address-cells = <1>;
			#size-cells = <0>;

			status = "disabled";

			cci1_i2c0: i2c-bus@0 {
				reg = <0>;
				clock-frequency = <1000000>;
				#address-cells = <1>;
				#size-cells = <0>;
			};

			cci1_i2c1: i2c-bus@1 {
				reg = <1>;
				clock-frequency = <1000000>;
				#address-cells = <1>;
				#size-cells = <0>;
			};
		};

		cci2: cci@ac15000 {
			compatible = "qcom,sa8775p-cci", "qcom,msm8996-cci";
			reg = <0x0 0x0ac15000 0x0 0x1000>;
			interrupts = <GIC_SPI 651 IRQ_TYPE_EDGE_RISING>;

			#address-cells = <1>;
			#size-cells = <0>;

			status = "disabled";

			cci2_i2c0: i2c-bus@0 {
				reg = <0>;
				clock-frequency = <1000000>;
				#address-cells = <1>;
				#size-cells = <0>;
			};

			cci2_i2c1: i2c-bus@1 {
				reg = <1>;
				clock-frequency = <1000000>;
				#address-cells = <1>;
				#size-cells = <0>;
			};
		};

		cci3: cci@ac16000 {
			compatible = "qcom,sa8775p-cci", "qcom,msm8996-cci";
			reg = <0x0 0x0ac16000 0x0 0x1000>;
			interrupts = <GIC_SPI 771 IRQ_TYPE_EDGE_RISING>;

			#address-cells = <1>;
			#size-cells = <0>;

			status = "disabled";

			cci3_i2c0: i2c-bus@0 {
				reg = <0>;
				clock-frequency = <1000000>;
				#address-cells = <1>;
				#size-cells = <0>;
			};

			cci3_i2c1: i2c-bus@1 {
				reg = <1>;
				clock-frequency = <1000000>;
				#address-cells = <1>;
				#size-cells = <0>;
			};
		};

		camss: isp@ac78000 {
			compatible = "qcom,sa8775p-camss";

			reg = <0x0 0xac78000 0x0 0x1000>,
			      <0x0 0xac7a000 0x0 0x0f00>,
			      <0x0 0xac7c000 0x0 0x0f00>,
			      <0x0 0xac84000 0x0 0x0f00>,
			      <0x0 0xac88000 0x0 0x0f00>,
			      <0x0 0xac8c000 0x0 0x0f00>,
			      <0x0 0xac90000 0x0 0x0f00>,
			      <0x0 0xac94000 0x0 0x0f00>,
			      <0x0 0xac9c000 0x0 0x2000>,
			      <0x0 0xac9e000 0x0 0x2000>,
			      <0x0 0xaca0000 0x0 0x2000>,
			      <0x0 0xaca2000 0x0 0x2000>,
			      <0x0 0xacac000 0x0 0x0400>,
			      <0x0 0xacad000 0x0 0x0400>,
			      <0x0 0xacae000 0x0 0x0400>,
			      <0x0 0xac4d000 0x0 0xd000>,
			      <0x0 0xac5a000 0x0 0xd000>,
			      <0x0 0xac85000 0x0 0x0d00>,
			      <0x0 0xac89000 0x0 0x0d00>,
			      <0x0 0xac8d000 0x0 0x0d00>,
			      <0x0 0xac91000 0x0 0x0d00>,
			      <0x0 0xac95000 0x0 0x0d00>;
			reg-names = "csid_wrapper",
				    "csid0",
				    "csid1",
				    "csid_lite0",
				    "csid_lite1",
				    "csid_lite2",
				    "csid_lite3",
				    "csid_lite4",
				    "csiphy0",
				    "csiphy1",
				    "csiphy2",
				    "csiphy3",
				    "tpg0",
				    "tpg1",
				    "tpg2",
				    "vfe0",
				    "vfe1",
				    "vfe_lite0",
				    "vfe_lite1",
				    "vfe_lite2",
				    "vfe_lite3",
				    "vfe_lite4";

			interrupts = <GIC_SPI 565 IRQ_TYPE_EDGE_RISING>,
				     <GIC_SPI 564 IRQ_TYPE_EDGE_RISING>,
				     <GIC_SPI 468 IRQ_TYPE_EDGE_RISING>,
				     <GIC_SPI 359 IRQ_TYPE_EDGE_RISING>,
				     <GIC_SPI 759 IRQ_TYPE_EDGE_RISING>,
				     <GIC_SPI 758 IRQ_TYPE_EDGE_RISING>,
				     <GIC_SPI 604 IRQ_TYPE_EDGE_RISING>,
				     <GIC_SPI 477 IRQ_TYPE_EDGE_RISING>,
				     <GIC_SPI 478 IRQ_TYPE_EDGE_RISING>,
				     <GIC_SPI 479 IRQ_TYPE_EDGE_RISING>,
				     <GIC_SPI 448 IRQ_TYPE_EDGE_RISING>,
				     <GIC_SPI 545 IRQ_TYPE_EDGE_RISING>,
				     <GIC_SPI 546 IRQ_TYPE_EDGE_RISING>,
				     <GIC_SPI 547 IRQ_TYPE_EDGE_RISING>,
				     <GIC_SPI 465 IRQ_TYPE_EDGE_RISING>,
				     <GIC_SPI 467 IRQ_TYPE_EDGE_RISING>,
				     <GIC_SPI 469 IRQ_TYPE_EDGE_RISING>,
				     <GIC_SPI 360 IRQ_TYPE_EDGE_RISING>,
				     <GIC_SPI 761 IRQ_TYPE_EDGE_RISING>,
				     <GIC_SPI 760 IRQ_TYPE_EDGE_RISING>,
				     <GIC_SPI 605 IRQ_TYPE_EDGE_RISING>;
			interrupt-names = "csid0",
					  "csid1",
					  "csid_lite0",
					  "csid_lite1",
					  "csid_lite2",
					  "csid_lite3",
					  "csid_lite4",
					  "csiphy0",
					  "csiphy1",
					  "csiphy2",
					  "csiphy3",
					  "tpg0",
					  "tpg1",
					  "tpg2",
					  "vfe0",
					  "vfe1",
					  "vfe_lite0",
					  "vfe_lite1",
					  "vfe_lite2",
					  "vfe_lite3",
					  "vfe_lite4";

			iommus = <&apps_smmu 0x3400 0x20>;

			status = "disabled";

			ports {
				#address-cells = <1>;
				#size-cells = <0>;

				port@0 {
					reg = <0>;
				};

				port@1 {
					reg = <1>;
				};

				port@2 {
					reg = <2>;
				};

				port@3 {
					reg = <3>;
				};
			};
		};

		mdss0: display-subsystem@ae00000 {
			compatible = "qcom,sa8775p-mdss";
			reg = <0x0 0x0ae00000 0x0 0x1000>;
			reg-names = "mdss";

			interrupts = <GIC_SPI 92 IRQ_TYPE_LEVEL_HIGH>;
			interrupt-controller;
			#interrupt-cells = <1>;

			iommus = <&apps_smmu 0x1000 0x402>;

			#address-cells = <2>;
			#size-cells = <2>;
			ranges;

			status = "disabled";

			mdss0_mdp: display-controller@ae01000 {
				compatible = "qcom,sa8775p-dpu";
				reg = <0x0 0x0ae01000 0x0 0x8f000>,
				      <0x0 0x0aeb0000 0x0 0x3000>;
				reg-names = "mdp", "vbif";

				interrupt-parent = <&mdss0>;
				interrupts = <0>;

				ports {
					#address-cells = <1>;
					#size-cells = <0>;

					port@0 {
						reg = <0>;

						dpu_intf0_out: endpoint {
							remote-endpoint = <&mdss0_dp0_in>;
						};
					};

					port@1 {
						reg = <1>;

						dpu_intf4_out: endpoint {
							remote-endpoint = <&mdss0_dp1_in>;
						};
					};

					port@2 {
						reg = <2>;

						dpu_intf1_out: endpoint {
							remote-endpoint = <&mdss0_dsi0_in>;
						};
					};

					port@3 {
						reg = <3>;

						dpu_intf2_out: endpoint {
							remote-endpoint = <&mdss0_dsi1_in>;
						};
					};
				};
			};

			mdss0_dsi0: dsi@ae94000 {
				compatible = "qcom,sa8775p-dsi-ctrl", "qcom,mdss-dsi-ctrl";
				reg = <0x0 0x0ae94000 0x0 0x400>;
				reg-names = "dsi_ctrl";

				interrupt-parent = <&mdss0>;
				interrupts = <4>;

				#address-cells = <1>;
				#size-cells = <0>;

				status = "disabled";

				ports {
					#address-cells = <1>;
					#size-cells = <0>;

					port@0 {
						reg = <0>;

						mdss0_dsi0_in: endpoint {
							remote-endpoint = <&dpu_intf1_out>;
						};
					};

					port@1 {
						reg = <1>;

						mdss0_dsi0_out: endpoint { };
					};
				};
			};

			mdss0_dsi1: dsi@ae96000 {
				compatible = "qcom,sa8775p-dsi-ctrl", "qcom,mdss-dsi-ctrl";
				reg = <0x0 0x0ae96000 0x0 0x400>;
				reg-names = "dsi_ctrl";

				interrupt-parent = <&mdss0>;
				interrupts = <5>;

				#address-cells = <1>;
				#size-cells = <0>;

				status = "disabled";

				ports {
					#address-cells = <1>;
					#size-cells = <0>;

					port@0 {
						reg = <0>;

						mdss0_dsi1_in: endpoint {
							remote-endpoint = <&dpu_intf2_out>;
						};
					};

					port@1 {
						reg = <1>;

						mdss0_dsi1_out: endpoint { };
					};
				};
			};

			mdss0_dp0: displayport-controller@af54000 {
				compatible = "qcom,sa8775p-dp";

				reg = <0x0 0x0af54000 0x0 0x104>,
				      <0x0 0x0af54200 0x0 0x0c0>,
				      <0x0 0x0af55000 0x0 0x770>,
				      <0x0 0x0af56000 0x0 0x09c>,
				      <0x0 0x0af57000 0x0 0x09c>,
				      <0x0 0x0af58000 0x0 0x09c>,
				      <0x0 0x0af59000 0x0 0x09c>,
				      <0x0 0x0af5a000 0x0 0x23c>,
				      <0x0 0x0af5b000 0x0 0x23c>;

				interrupt-parent = <&mdss0>;
				interrupts = <12>;

				#sound-dai-cells = <0>;

				status = "disabled";

				ports {
					#address-cells = <1>;
					#size-cells = <0>;

					port@0 {
						reg = <0>;

						mdss0_dp0_in: endpoint {
							remote-endpoint = <&dpu_intf0_out>;
						};
					};

					port@1 {
						reg = <1>;

						mdss0_dp0_out: endpoint { };
					};
				};
			};

			mdss0_dp1: displayport-controller@af5c000 {
				compatible = "qcom,sa8775p-dp";

				reg = <0x0 0x0af5c000 0x0 0x104>,
				      <0x0 0x0af5c200 0x0 0x0c0>,
				      <0x0 0x0af5d000 0x0 0x770>,
				      <0x0 0x0af5e000 0x0 0x09c>,
				      <0x0 0x0af5f000 0x0 0x09c>,
				      <0x0 0x0af60000 0x0 0x09c>,
				      <0x0 0x0af61000 0x0 0x09c>,
				      <0x0 0x0af62000 0x0 0x23c>,
				      <0x0 0x0af63000 0x0 0x23c>;

				interrupt-parent = <&mdss0>;
				interrupts = <13>;

				#sound-dai-cells = <0>;

				status = "disabled";

				ports {
					#address-cells = <1>;
					#size-cells = <0>;

					port@0 {
						reg = <0>;

						mdss0_dp1_in: endpoint {
							remote-endpoint = <&dpu_intf4_out>;
						};
					};

					port@1 {
						reg = <1>;

						mdss0_dp1_out: endpoint { };
					};
				};
			};
		};

		pdc: interrupt-controller@b220000 {
			compatible = "qcom,sa8775p-pdc", "qcom,pdc";
			reg = <0x0 0x0b220000 0x0 0x10000>,
			      <0x0 0x17c000f0 0x0 0x64>;
			qcom,pdc-ranges = <0 480 40>,
					  <40 140 14>,
					  <54 263 1>,
					  <55 306 4>,
					  <59 312 3>,
					  <62 374 2>,
					  <64 434 2>,
					  <66 438 2>,
					  <70 520 1>,
					  <73 523 1>,
					  <118 568 6>,
					  <124 609 3>,
					  <159 638 1>,
					  <160 720 3>,
					  <169 728 30>,
					  <199 416 2>,
					  <201 449 1>,
					  <202 89 1>,
					  <203 451 1>,
					  <204 462 1>,
					  <205 264 1>,
					  <206 579 1>,
					  <207 653 1>,
					  <208 656 1>,
					  <209 659 1>,
					  <210 122 1>,
					  <211 699 1>,
					  <212 705 1>,
					  <213 450 1>,
					  <214 643 2>,
					  <216 646 5>,
					  <221 390 5>,
					  <226 700 2>,
					  <228 440 1>,
					  <229 663 1>,
					  <230 524 2>,
					  <232 612 3>,
					  <235 723 5>;
			#interrupt-cells = <2>;
			interrupt-parent = <&intc>;
			interrupt-controller;
		};

		tsens2: thermal-sensor@c251000 {
			compatible = "qcom,sa8775p-tsens", "qcom,tsens-v2";
			reg = <0x0 0x0c251000 0x0 0x1ff>,
			      <0x0 0x0c224000 0x0 0x8>;
			interrupts = <GIC_SPI 572 IRQ_TYPE_LEVEL_HIGH>,
				     <GIC_SPI 609 IRQ_TYPE_LEVEL_HIGH>;
			#qcom,sensors = <13>;
			interrupt-names = "uplow", "critical";
			#thermal-sensor-cells = <1>;
		};

		tsens3: thermal-sensor@c252000 {
			compatible = "qcom,sa8775p-tsens", "qcom,tsens-v2";
			reg = <0x0 0x0c252000 0x0 0x1ff>,
			      <0x0 0x0c225000 0x0 0x8>;
			interrupts = <GIC_SPI 573 IRQ_TYPE_LEVEL_HIGH>,
				     <GIC_SPI 610 IRQ_TYPE_LEVEL_HIGH>;
			#qcom,sensors = <13>;
			interrupt-names = "uplow", "critical";
			#thermal-sensor-cells = <1>;
		};

		tsens0: thermal-sensor@c263000 {
			compatible = "qcom,sa8775p-tsens", "qcom,tsens-v2";
			reg = <0x0 0x0c263000 0x0 0x1ff>,
			      <0x0 0x0c222000 0x0 0x8>;
			interrupts = <GIC_SPI 506 IRQ_TYPE_LEVEL_HIGH>,
				     <GIC_SPI 508 IRQ_TYPE_LEVEL_HIGH>;
			#qcom,sensors = <12>;
			interrupt-names = "uplow", "critical";
			#thermal-sensor-cells = <1>;
		};

		tsens1: thermal-sensor@c265000 {
			compatible = "qcom,sa8775p-tsens", "qcom,tsens-v2";
			reg = <0x0 0x0c265000 0x0 0x1ff>,
			      <0x0 0x0c223000 0x0 0x8>;
			interrupts = <GIC_SPI 507 IRQ_TYPE_LEVEL_HIGH>,
				     <GIC_SPI 509 IRQ_TYPE_LEVEL_HIGH>;
			#qcom,sensors = <12>;
			interrupt-names = "uplow", "critical";
			#thermal-sensor-cells = <1>;
		};

		aoss_qmp: power-management@c300000 {
			compatible = "qcom,sa8775p-aoss-qmp", "qcom,aoss-qmp";
			reg = <0x0 0x0c300000 0x0 0x400>;
			interrupts-extended = <&ipcc IPCC_CLIENT_AOP
					       IPCC_MPROC_SIGNAL_GLINK_QMP
					       IRQ_TYPE_EDGE_RISING>;
			mboxes = <&ipcc IPCC_CLIENT_AOP IPCC_MPROC_SIGNAL_GLINK_QMP>;
			#clock-cells = <0>;
		};

		sram@c3f0000 {
			compatible = "qcom,rpmh-stats";
			reg = <0x0 0x0c3f0000 0x0 0x400>;
		};

		spmi_bus: spmi@c440000 {
			compatible = "qcom,spmi-pmic-arb";
			reg = <0x0 0x0c440000 0x0 0x1100>,
			      <0x0 0x0c600000 0x0 0x2000000>,
			      <0x0 0x0e600000 0x0 0x100000>,
			      <0x0 0x0e700000 0x0 0xa0000>,
			      <0x0 0x0c40a000 0x0 0x26000>;
			reg-names = "core",
				    "chnls",
				    "obsrvr",
				    "intr",
				    "cnfg";
			qcom,channel = <0>;
			qcom,ee = <0>;
			interrupts-extended = <&pdc 1 IRQ_TYPE_LEVEL_HIGH>;
			interrupt-names = "periph_irq";
			interrupt-controller;
			#interrupt-cells = <4>;
			#address-cells = <2>;
			#size-cells = <0>;
		};

		tlmm: pinctrl@f000000 {
			compatible = "qcom,sa8775p-tlmm";
			reg = <0x0 0x0f000000 0x0 0x1000000>;
			interrupts = <GIC_SPI 208 IRQ_TYPE_LEVEL_HIGH>;
			gpio-controller;
			#gpio-cells = <2>;
			interrupt-controller;
			#interrupt-cells = <2>;
			gpio-ranges = <&tlmm 0 0 149>;
			wakeup-parent = <&pdc>;
		};

		sram: sram@146d8000 {
			compatible = "qcom,sa8775p-imem", "syscon", "simple-mfd";
			reg = <0x0 0x146d8000 0x0 0x1000>;
			ranges = <0x0 0x0 0x146d8000 0x1000>;

			#address-cells = <1>;
			#size-cells = <1>;

			minidump_config: minidump-sram@1c {
				reg = <0x1c 0x4>;
			};

			pil-reloc@94c {
				compatible = "qcom,pil-reloc-info";
				reg = <0x94c 0xc8>;
			};
		};

		apps_smmu: iommu@15000000 {
			compatible = "qcom,sa8775p-smmu-500", "qcom,smmu-500", "arm,mmu-500";
			reg = <0x0 0x15000000 0x0 0x100000>;
			#iommu-cells = <2>;
			#global-interrupts = <2>;
			dma-coherent;

			interrupts = <GIC_SPI 119 IRQ_TYPE_LEVEL_HIGH>,
				     <GIC_SPI 120 IRQ_TYPE_LEVEL_HIGH>,
				     <GIC_SPI 102 IRQ_TYPE_LEVEL_HIGH>,
				     <GIC_SPI 103 IRQ_TYPE_LEVEL_HIGH>,
				     <GIC_SPI 104 IRQ_TYPE_LEVEL_HIGH>,
				     <GIC_SPI 105 IRQ_TYPE_LEVEL_HIGH>,
				     <GIC_SPI 106 IRQ_TYPE_LEVEL_HIGH>,
				     <GIC_SPI 107 IRQ_TYPE_LEVEL_HIGH>,
				     <GIC_SPI 108 IRQ_TYPE_LEVEL_HIGH>,
				     <GIC_SPI 109 IRQ_TYPE_LEVEL_HIGH>,
				     <GIC_SPI 110 IRQ_TYPE_LEVEL_HIGH>,
				     <GIC_SPI 111 IRQ_TYPE_LEVEL_HIGH>,
				     <GIC_SPI 112 IRQ_TYPE_LEVEL_HIGH>,
				     <GIC_SPI 113 IRQ_TYPE_LEVEL_HIGH>,
				     <GIC_SPI 114 IRQ_TYPE_LEVEL_HIGH>,
				     <GIC_SPI 115 IRQ_TYPE_LEVEL_HIGH>,
				     <GIC_SPI 116 IRQ_TYPE_LEVEL_HIGH>,
				     <GIC_SPI 117 IRQ_TYPE_LEVEL_HIGH>,
				     <GIC_SPI 118 IRQ_TYPE_LEVEL_HIGH>,
				     <GIC_SPI 181 IRQ_TYPE_LEVEL_HIGH>,
				     <GIC_SPI 182 IRQ_TYPE_LEVEL_HIGH>,
				     <GIC_SPI 183 IRQ_TYPE_LEVEL_HIGH>,
				     <GIC_SPI 184 IRQ_TYPE_LEVEL_HIGH>,
				     <GIC_SPI 185 IRQ_TYPE_LEVEL_HIGH>,
				     <GIC_SPI 186 IRQ_TYPE_LEVEL_HIGH>,
				     <GIC_SPI 187 IRQ_TYPE_LEVEL_HIGH>,
				     <GIC_SPI 188 IRQ_TYPE_LEVEL_HIGH>,
				     <GIC_SPI 189 IRQ_TYPE_LEVEL_HIGH>,
				     <GIC_SPI 190 IRQ_TYPE_LEVEL_HIGH>,
				     <GIC_SPI 191 IRQ_TYPE_LEVEL_HIGH>,
				     <GIC_SPI 192 IRQ_TYPE_LEVEL_HIGH>,
				     <GIC_SPI 315 IRQ_TYPE_LEVEL_HIGH>,
				     <GIC_SPI 316 IRQ_TYPE_LEVEL_HIGH>,
				     <GIC_SPI 317 IRQ_TYPE_LEVEL_HIGH>,
				     <GIC_SPI 318 IRQ_TYPE_LEVEL_HIGH>,
				     <GIC_SPI 319 IRQ_TYPE_LEVEL_HIGH>,
				     <GIC_SPI 320 IRQ_TYPE_LEVEL_HIGH>,
				     <GIC_SPI 321 IRQ_TYPE_LEVEL_HIGH>,
				     <GIC_SPI 322 IRQ_TYPE_LEVEL_HIGH>,
				     <GIC_SPI 323 IRQ_TYPE_LEVEL_HIGH>,
				     <GIC_SPI 324 IRQ_TYPE_LEVEL_HIGH>,
				     <GIC_SPI 325 IRQ_TYPE_LEVEL_HIGH>,
				     <GIC_SPI 326 IRQ_TYPE_LEVEL_HIGH>,
				     <GIC_SPI 327 IRQ_TYPE_LEVEL_HIGH>,
				     <GIC_SPI 328 IRQ_TYPE_LEVEL_HIGH>,
				     <GIC_SPI 329 IRQ_TYPE_LEVEL_HIGH>,
				     <GIC_SPI 330 IRQ_TYPE_LEVEL_HIGH>,
				     <GIC_SPI 331 IRQ_TYPE_LEVEL_HIGH>,
				     <GIC_SPI 332 IRQ_TYPE_LEVEL_HIGH>,
				     <GIC_SPI 333 IRQ_TYPE_LEVEL_HIGH>,
				     <GIC_SPI 334 IRQ_TYPE_LEVEL_HIGH>,
				     <GIC_SPI 335 IRQ_TYPE_LEVEL_HIGH>,
				     <GIC_SPI 336 IRQ_TYPE_LEVEL_HIGH>,
				     <GIC_SPI 337 IRQ_TYPE_LEVEL_HIGH>,
				     <GIC_SPI 338 IRQ_TYPE_LEVEL_HIGH>,
				     <GIC_SPI 339 IRQ_TYPE_LEVEL_HIGH>,
				     <GIC_SPI 340 IRQ_TYPE_LEVEL_HIGH>,
				     <GIC_SPI 341 IRQ_TYPE_LEVEL_HIGH>,
				     <GIC_SPI 342 IRQ_TYPE_LEVEL_HIGH>,
				     <GIC_SPI 343 IRQ_TYPE_LEVEL_HIGH>,
				     <GIC_SPI 344 IRQ_TYPE_LEVEL_HIGH>,
				     <GIC_SPI 345 IRQ_TYPE_LEVEL_HIGH>,
				     <GIC_SPI 395 IRQ_TYPE_LEVEL_HIGH>,
				     <GIC_SPI 396 IRQ_TYPE_LEVEL_HIGH>,
				     <GIC_SPI 397 IRQ_TYPE_LEVEL_HIGH>,
				     <GIC_SPI 398 IRQ_TYPE_LEVEL_HIGH>,
				     <GIC_SPI 399 IRQ_TYPE_LEVEL_HIGH>,
				     <GIC_SPI 400 IRQ_TYPE_LEVEL_HIGH>,
				     <GIC_SPI 401 IRQ_TYPE_LEVEL_HIGH>,
				     <GIC_SPI 402 IRQ_TYPE_LEVEL_HIGH>,
				     <GIC_SPI 403 IRQ_TYPE_LEVEL_HIGH>,
				     <GIC_SPI 404 IRQ_TYPE_LEVEL_HIGH>,
				     <GIC_SPI 405 IRQ_TYPE_LEVEL_HIGH>,
				     <GIC_SPI 406 IRQ_TYPE_LEVEL_HIGH>,
				     <GIC_SPI 407 IRQ_TYPE_LEVEL_HIGH>,
				     <GIC_SPI 408 IRQ_TYPE_LEVEL_HIGH>,
				     <GIC_SPI 409 IRQ_TYPE_LEVEL_HIGH>,
				     <GIC_SPI 418 IRQ_TYPE_LEVEL_HIGH>,
				     <GIC_SPI 419 IRQ_TYPE_LEVEL_HIGH>,
				     <GIC_SPI 412 IRQ_TYPE_LEVEL_HIGH>,
				     <GIC_SPI 421 IRQ_TYPE_LEVEL_HIGH>,
				     <GIC_SPI 706 IRQ_TYPE_LEVEL_HIGH>,
				     <GIC_SPI 423 IRQ_TYPE_LEVEL_HIGH>,
				     <GIC_SPI 424 IRQ_TYPE_LEVEL_HIGH>,
				     <GIC_SPI 425 IRQ_TYPE_LEVEL_HIGH>,
				     <GIC_SPI 689 IRQ_TYPE_LEVEL_HIGH>,
				     <GIC_SPI 690 IRQ_TYPE_LEVEL_HIGH>,
				     <GIC_SPI 691 IRQ_TYPE_LEVEL_HIGH>,
				     <GIC_SPI 692 IRQ_TYPE_LEVEL_HIGH>,
				     <GIC_SPI 693 IRQ_TYPE_LEVEL_HIGH>,
				     <GIC_SPI 694 IRQ_TYPE_LEVEL_HIGH>,
				     <GIC_SPI 695 IRQ_TYPE_LEVEL_HIGH>,
				     <GIC_SPI 696 IRQ_TYPE_LEVEL_HIGH>,
				     <GIC_SPI 410 IRQ_TYPE_LEVEL_HIGH>,
				     <GIC_SPI 411 IRQ_TYPE_LEVEL_HIGH>,
				     <GIC_SPI 420 IRQ_TYPE_LEVEL_HIGH>,
				     <GIC_SPI 413 IRQ_TYPE_LEVEL_HIGH>,
				     <GIC_SPI 422 IRQ_TYPE_LEVEL_HIGH>,
				     <GIC_SPI 707 IRQ_TYPE_LEVEL_HIGH>,
				     <GIC_SPI 708 IRQ_TYPE_LEVEL_HIGH>,
				     <GIC_SPI 709 IRQ_TYPE_LEVEL_HIGH>,
				     <GIC_SPI 710 IRQ_TYPE_LEVEL_HIGH>,
				     <GIC_SPI 711 IRQ_TYPE_LEVEL_HIGH>,
				     <GIC_SPI 414 IRQ_TYPE_LEVEL_HIGH>,
				     <GIC_SPI 712 IRQ_TYPE_LEVEL_HIGH>,
				     <GIC_SPI 713 IRQ_TYPE_LEVEL_HIGH>,
				     <GIC_SPI 714 IRQ_TYPE_LEVEL_HIGH>,
				     <GIC_SPI 715 IRQ_TYPE_LEVEL_HIGH>,
				     <GIC_SPI 912 IRQ_TYPE_LEVEL_HIGH>,
				     <GIC_SPI 911 IRQ_TYPE_LEVEL_HIGH>,
				     <GIC_SPI 910 IRQ_TYPE_LEVEL_HIGH>,
				     <GIC_SPI 909 IRQ_TYPE_LEVEL_HIGH>,
				     <GIC_SPI 908 IRQ_TYPE_LEVEL_HIGH>,
				     <GIC_SPI 907 IRQ_TYPE_LEVEL_HIGH>,
				     <GIC_SPI 906 IRQ_TYPE_LEVEL_HIGH>,
				     <GIC_SPI 905 IRQ_TYPE_LEVEL_HIGH>,
				     <GIC_SPI 904 IRQ_TYPE_LEVEL_HIGH>,
				     <GIC_SPI 903 IRQ_TYPE_LEVEL_HIGH>,
				     <GIC_SPI 902 IRQ_TYPE_LEVEL_HIGH>,
				     <GIC_SPI 901 IRQ_TYPE_LEVEL_HIGH>,
				     <GIC_SPI 900 IRQ_TYPE_LEVEL_HIGH>,
				     <GIC_SPI 899 IRQ_TYPE_LEVEL_HIGH>,
				     <GIC_SPI 898 IRQ_TYPE_LEVEL_HIGH>,
				     <GIC_SPI 897 IRQ_TYPE_LEVEL_HIGH>,
				     <GIC_SPI 896 IRQ_TYPE_LEVEL_HIGH>,
				     <GIC_SPI 895 IRQ_TYPE_LEVEL_HIGH>,
				     <GIC_SPI 894 IRQ_TYPE_LEVEL_HIGH>,
				     <GIC_SPI 893 IRQ_TYPE_LEVEL_HIGH>,
				     <GIC_SPI 892 IRQ_TYPE_LEVEL_HIGH>,
				     <GIC_SPI 891 IRQ_TYPE_LEVEL_HIGH>;
		};

		pcie_smmu: iommu@15200000 {
			compatible = "qcom,sa8775p-smmu-500", "qcom,smmu-500", "arm,mmu-500";
			reg = <0x0 0x15200000 0x0 0x80000>;
			#iommu-cells = <2>;
			#global-interrupts = <2>;
			dma-coherent;

			interrupts = <GIC_SPI 920 IRQ_TYPE_LEVEL_HIGH>,
				     <GIC_SPI 921 IRQ_TYPE_LEVEL_HIGH>,
				     <GIC_SPI 925 IRQ_TYPE_LEVEL_HIGH>,
				     <GIC_SPI 926 IRQ_TYPE_LEVEL_HIGH>,
				     <GIC_SPI 927 IRQ_TYPE_LEVEL_HIGH>,
				     <GIC_SPI 928 IRQ_TYPE_LEVEL_HIGH>,
				     <GIC_SPI 950 IRQ_TYPE_LEVEL_HIGH>,
				     <GIC_SPI 951 IRQ_TYPE_LEVEL_HIGH>,
				     <GIC_SPI 952 IRQ_TYPE_LEVEL_HIGH>,
				     <GIC_SPI 953 IRQ_TYPE_LEVEL_HIGH>,
				     <GIC_SPI 954 IRQ_TYPE_LEVEL_HIGH>,
				     <GIC_SPI 955 IRQ_TYPE_LEVEL_HIGH>,
				     <GIC_SPI 956 IRQ_TYPE_LEVEL_HIGH>,
				     <GIC_SPI 957 IRQ_TYPE_LEVEL_HIGH>,
				     <GIC_SPI 958 IRQ_TYPE_LEVEL_HIGH>,
				     <GIC_SPI 885 IRQ_TYPE_LEVEL_HIGH>,
				     <GIC_SPI 886 IRQ_TYPE_LEVEL_HIGH>,
				     <GIC_SPI 887 IRQ_TYPE_LEVEL_HIGH>,
				     <GIC_SPI 888 IRQ_TYPE_LEVEL_HIGH>,
				     <GIC_SPI 820 IRQ_TYPE_LEVEL_HIGH>,
				     <GIC_SPI 822 IRQ_TYPE_LEVEL_HIGH>,
				     <GIC_SPI 823 IRQ_TYPE_LEVEL_HIGH>,
				     <GIC_SPI 310 IRQ_TYPE_LEVEL_HIGH>,
				     <GIC_SPI 446 IRQ_TYPE_LEVEL_HIGH>,
				     <GIC_SPI 447 IRQ_TYPE_LEVEL_HIGH>,
				     <GIC_SPI 452 IRQ_TYPE_LEVEL_HIGH>,
				     <GIC_SPI 840 IRQ_TYPE_LEVEL_HIGH>,
				     <GIC_SPI 841 IRQ_TYPE_LEVEL_HIGH>,
				     <GIC_SPI 842 IRQ_TYPE_LEVEL_HIGH>,
				     <GIC_SPI 843 IRQ_TYPE_LEVEL_HIGH>,
				     <GIC_SPI 844 IRQ_TYPE_LEVEL_HIGH>,
				     <GIC_SPI 845 IRQ_TYPE_LEVEL_HIGH>,
				     <GIC_SPI 846 IRQ_TYPE_LEVEL_HIGH>,
				     <GIC_SPI 847 IRQ_TYPE_LEVEL_HIGH>,
				     <GIC_SPI 848 IRQ_TYPE_LEVEL_HIGH>,
				     <GIC_SPI 849 IRQ_TYPE_LEVEL_HIGH>,
				     <GIC_SPI 802 IRQ_TYPE_LEVEL_HIGH>,
				     <GIC_SPI 803 IRQ_TYPE_LEVEL_HIGH>,
				     <GIC_SPI 804 IRQ_TYPE_LEVEL_HIGH>,
				     <GIC_SPI 805 IRQ_TYPE_LEVEL_HIGH>,
				     <GIC_SPI 806 IRQ_TYPE_LEVEL_HIGH>,
				     <GIC_SPI 807 IRQ_TYPE_LEVEL_HIGH>,
				     <GIC_SPI 808 IRQ_TYPE_LEVEL_HIGH>,
				     <GIC_SPI 809 IRQ_TYPE_LEVEL_HIGH>,
				     <GIC_SPI 810 IRQ_TYPE_LEVEL_HIGH>,
				     <GIC_SPI 811 IRQ_TYPE_LEVEL_HIGH>,
				     <GIC_SPI 812 IRQ_TYPE_LEVEL_HIGH>,
				     <GIC_SPI 813 IRQ_TYPE_LEVEL_HIGH>,
				     <GIC_SPI 814 IRQ_TYPE_LEVEL_HIGH>,
				     <GIC_SPI 836 IRQ_TYPE_LEVEL_HIGH>,
				     <GIC_SPI 837 IRQ_TYPE_LEVEL_HIGH>,
				     <GIC_SPI 838 IRQ_TYPE_LEVEL_HIGH>,
				     <GIC_SPI 839 IRQ_TYPE_LEVEL_HIGH>,
				     <GIC_SPI 854 IRQ_TYPE_LEVEL_HIGH>,
				     <GIC_SPI 855 IRQ_TYPE_LEVEL_HIGH>,
				     <GIC_SPI 856 IRQ_TYPE_LEVEL_HIGH>,
				     <GIC_SPI 790 IRQ_TYPE_LEVEL_HIGH>,
				     <GIC_SPI 791 IRQ_TYPE_LEVEL_HIGH>,
				     <GIC_SPI 792 IRQ_TYPE_LEVEL_HIGH>,
				     <GIC_SPI 793 IRQ_TYPE_LEVEL_HIGH>,
				     <GIC_SPI 794 IRQ_TYPE_LEVEL_HIGH>,
				     <GIC_SPI 795 IRQ_TYPE_LEVEL_HIGH>,
				     <GIC_SPI 796 IRQ_TYPE_LEVEL_HIGH>,
				     <GIC_SPI 639 IRQ_TYPE_LEVEL_HIGH>,
				     <GIC_SPI 79 IRQ_TYPE_LEVEL_HIGH>,
				     <GIC_SPI 640 IRQ_TYPE_LEVEL_HIGH>;
		};

		intc: interrupt-controller@17a00000 {
			compatible = "arm,gic-v3";
			reg = <0x0 0x17a00000 0x0 0x10000>,     /* GICD */
			      <0x0 0x17a60000 0x0 0x100000>;    /* GICR * 8 */
			interrupt-controller;
			#address-cells = <0>;
			#interrupt-cells = <3>;
			interrupts = <GIC_PPI 9 IRQ_TYPE_LEVEL_HIGH>;
			#redistributor-regions = <1>;
			redistributor-stride = <0x0 0x20000>;
		};

		watchdog@17c10000 {
			compatible = "qcom,apss-wdt-sa8775p", "qcom,kpss-wdt";
			reg = <0x0 0x17c10000 0x0 0x1000>;
			clocks = <&sleep_clk>;
			interrupts = <GIC_SPI 0 IRQ_TYPE_EDGE_RISING>;
		};

		memtimer: timer@17c20000 {
			compatible = "arm,armv7-timer-mem";
			reg = <0x0 0x17c20000 0x0 0x1000>;
			ranges = <0x0 0x0 0x0 0x20000000>;
			#address-cells = <1>;
			#size-cells = <1>;

			frame@17c21000 {
				reg = <0x17c21000 0x1000>,
				      <0x17c22000 0x1000>;
				interrupts = <GIC_SPI 8 IRQ_TYPE_LEVEL_HIGH>,
					     <GIC_SPI 6 IRQ_TYPE_LEVEL_HIGH>;
				frame-number = <0>;
			};

			frame@17c23000 {
				reg = <0x17c23000 0x1000>;
				interrupts = <GIC_SPI 9 IRQ_TYPE_LEVEL_HIGH>;
				frame-number = <1>;
				status = "disabled";
			};

			frame@17c25000 {
				reg = <0x17c25000 0x1000>;
				interrupts = <GIC_SPI 10 IRQ_TYPE_LEVEL_HIGH>;
				frame-number = <2>;
				status = "disabled";
			};

			frame@17c27000 {
				reg = <0x17c27000 0x1000>;
				interrupts = <GIC_SPI 11 IRQ_TYPE_LEVEL_HIGH>;
				frame-number = <3>;
				status = "disabled";
			};

			frame@17c29000 {
				reg = <0x17c29000 0x1000>;
				interrupts = <GIC_SPI 12 IRQ_TYPE_LEVEL_HIGH>;
				frame-number = <4>;
				status = "disabled";
			};

			frame@17c2b000 {
				reg = <0x17c2b000 0x1000>;
				interrupts = <GIC_SPI 13 IRQ_TYPE_LEVEL_HIGH>;
				frame-number = <5>;
				status = "disabled";
			};

			frame@17c2d000 {
				reg = <0x17c2d000 0x1000>;
				interrupts = <GIC_SPI 14 IRQ_TYPE_LEVEL_HIGH>;
				frame-number = <6>;
				status = "disabled";
			};
		};

		cpufreq_hw: cpufreq@18591000 {
			compatible = "qcom,sa8775p-cpufreq-epss",
				     "qcom,cpufreq-epss";
			reg = <0x0 0x18591000 0x0 0x1000>,
			      <0x0 0x18593000 0x0 0x1000>;
			reg-names = "freq-domain0", "freq-domain1";

			interrupts = <GIC_SPI 31 IRQ_TYPE_LEVEL_HIGH>,
				     <GIC_SPI 32 IRQ_TYPE_LEVEL_HIGH>;
			interrupt-names = "dcvsh-irq-0", "dcvsh-irq-1";

			#freq-domain-cells = <1>;
		};

		remoteproc_gpdsp0: remoteproc@20c00000 {
			compatible = "qcom,sa8775p-gpdsp0-pas";
			reg = <0x0 0x20c00000 0x0 0x10000>;

			interrupts-extended = <&intc GIC_SPI 768 IRQ_TYPE_EDGE_RISING>,
					      <&smp2p_gpdsp0_in 0 0>,
					      <&smp2p_gpdsp0_in 1 0>,
					      <&smp2p_gpdsp0_in 2 0>,
					      <&smp2p_gpdsp0_in 3 0>;
			interrupt-names = "wdog", "fatal", "ready",
					  "handover", "stop-ack";

			memory-region = <&pil_gdsp0_mem>;

			qcom,qmp = <&aoss_qmp>;

			qcom,smem-states = <&smp2p_gpdsp0_out 0>;
			qcom,smem-state-names = "stop";

			status = "disabled";

			glink-edge {
				interrupts-extended = <&ipcc IPCC_CLIENT_GPDSP0
							     IPCC_MPROC_SIGNAL_GLINK_QMP
							     IRQ_TYPE_EDGE_RISING>;
				mboxes = <&ipcc IPCC_CLIENT_GPDSP0
						IPCC_MPROC_SIGNAL_GLINK_QMP>;

				label = "gpdsp0";
				qcom,remote-pid = <17>;

				fastrpc {
					compatible = "qcom,fastrpc";
					qcom,glink-channels = "fastrpcglink-apps-dsp";
					label = "gdsp0";
					#address-cells = <1>;
					#size-cells = <0>;

					compute-cb@1 {
						compatible = "qcom,fastrpc-compute-cb";
						reg = <1>;
						iommus = <&apps_smmu 0x38a1 0x0>;
						dma-coherent;
					};

					compute-cb@2 {
						compatible = "qcom,fastrpc-compute-cb";
						reg = <2>;
						iommus = <&apps_smmu 0x38a2 0x0>;
						dma-coherent;
					};

					compute-cb@3 {
						compatible = "qcom,fastrpc-compute-cb";
						reg = <3>;
						iommus = <&apps_smmu 0x38a3 0x0>;
						dma-coherent;
					};
				};
			};
		};

		remoteproc_gpdsp1: remoteproc@21c00000 {
			compatible = "qcom,sa8775p-gpdsp1-pas";
			reg = <0x0 0x21c00000 0x0 0x10000>;

			interrupts-extended = <&intc GIC_SPI 624 IRQ_TYPE_EDGE_RISING>,
					      <&smp2p_gpdsp1_in 0 0>,
					      <&smp2p_gpdsp1_in 1 0>,
					      <&smp2p_gpdsp1_in 2 0>,
					      <&smp2p_gpdsp1_in 3 0>;
			interrupt-names = "wdog", "fatal", "ready",
					  "handover", "stop-ack";

			memory-region = <&pil_gdsp1_mem>;

			qcom,qmp = <&aoss_qmp>;

			qcom,smem-states = <&smp2p_gpdsp1_out 0>;
			qcom,smem-state-names = "stop";

			status = "disabled";

			glink-edge {
				interrupts-extended = <&ipcc IPCC_CLIENT_GPDSP1
							     IPCC_MPROC_SIGNAL_GLINK_QMP
							     IRQ_TYPE_EDGE_RISING>;
				mboxes = <&ipcc IPCC_CLIENT_GPDSP1
						IPCC_MPROC_SIGNAL_GLINK_QMP>;

				label = "gpdsp1";
				qcom,remote-pid = <18>;

				fastrpc {
					compatible = "qcom,fastrpc";
					qcom,glink-channels = "fastrpcglink-apps-dsp";
					label = "gdsp1";
					#address-cells = <1>;
					#size-cells = <0>;

					compute-cb@1 {
						compatible = "qcom,fastrpc-compute-cb";
						reg = <1>;
						iommus = <&apps_smmu 0x38c1 0x0>;
						dma-coherent;
					};

					compute-cb@2 {
						compatible = "qcom,fastrpc-compute-cb";
						reg = <2>;
						iommus = <&apps_smmu 0x38c2 0x0>;
						dma-coherent;
					};

					compute-cb@3 {
						compatible = "qcom,fastrpc-compute-cb";
						reg = <3>;
						iommus = <&apps_smmu 0x38c3 0x0>;
						dma-coherent;
					};
				};
			};
		};

		mdss1: display-subsystem@22000000 {
			compatible = "qcom,sa8775p-mdss";
			reg = <0x0 0x22000000 0x0 0x1000>;
			reg-names = "mdss";

			interrupts = <GIC_SPI 865 IRQ_TYPE_LEVEL_HIGH>;
			interrupt-controller;
			#interrupt-cells = <1>;

			iommus = <&apps_smmu 0x1800 0x402>;

			#address-cells = <2>;
			#size-cells = <2>;
			ranges;

			status = "disabled";

			mdss1_mdp: display-controller@22001000 {
				compatible = "qcom,sa8775p-dpu";
				reg = <0x0 0x22001000 0x0 0x8f000>,
				      <0x0 0x220b0000 0x0 0x3000>;
				reg-names = "mdp", "vbif";

				interrupt-parent = <&mdss1>;
				interrupts = <0>;

				ports {
					#address-cells = <1>;
					#size-cells = <0>;

					port@0 {
						reg = <0>;

						dpu1_intf0_out: endpoint {
							remote-endpoint = <&mdss1_dp0_in>;
						};
					};

					port@1 {
						reg = <1>;

						dpu1_intf4_out: endpoint {
							remote-endpoint = <&mdss1_dp1_in>;
						};
					};
				};
			};

			mdss1_dp0: displayport-controller@22154000 {
				compatible = "qcom,sa8775p-dp";
				reg = <0x0 0x22154000 0x0 0x104>,
				      <0x0 0x22154200 0x0 0x0c0>,
				      <0x0 0x22155000 0x0 0x770>,
				      <0x0 0x22156000 0x0 0x09c>,
				      <0x0 0x22157000 0x0 0x09c>,
				      <0x0 0x22158000 0x0 0x09c>,
				      <0x0 0x22159000 0x0 0x09c>,
				      <0x0 0x2215a000 0x0 0x23c>,
				      <0x0 0x2215b000 0x0 0x23c>;

				interrupt-parent = <&mdss1>;
				interrupts = <12>;

				#sound-dai-cells = <0>;

				status = "disabled";

				ports {
					#address-cells = <1>;
					#size-cells = <0>;

					port@0 {
						reg = <0>;

						mdss1_dp0_in: endpoint {
							remote-endpoint = <&dpu1_intf0_out>;
						};
					};

					port@1 {
						reg = <1>;

						mdss1_dp0_out: endpoint { };
					};
				};
			};

			mdss1_dp1: displayport-controller@2215c000 {
				compatible = "qcom,sa8775p-dp";
				reg = <0x0 0x2215c000 0x0 0x104>,
				      <0x0 0x2215c200 0x0 0x0c0>,
				      <0x0 0x2215d000 0x0 0x770>,
				      <0x0 0x2215e000 0x0 0x09c>,
				      <0x0 0x2215f000 0x0 0x09c>,
				      <0x0 0x22160000 0x0 0x09c>,
				      <0x0 0x22161000 0x0 0x09c>,
				      <0x0 0x22162000 0x0 0x23c>,
				      <0x0 0x22163000 0x0 0x23c>;

				interrupt-parent = <&mdss1>;
				interrupts = <13>;

				#sound-dai-cells = <0>;

				status = "disabled";

				ports {
					#address-cells = <1>;
					#size-cells = <0>;

					port@0 {
						reg = <0>;

						mdss1_dp1_in: endpoint {
							remote-endpoint = <&dpu1_intf4_out>;
						};
					};

					port@1 {
						reg = <1>;

						mdss1_dp1_out: endpoint { };
					};
				};

			};
		};

		ethernet1: ethernet@23000000 {
			compatible = "qcom,sa8775p-ethqos";
			reg = <0x0 0x23000000 0x0 0x10000>,
			      <0x0 0x23016000 0x0 0x100>;
			reg-names = "stmmaceth", "rgmii";

			interrupts = <GIC_SPI 929 IRQ_TYPE_LEVEL_HIGH>,
				     <GIC_SPI 781 IRQ_TYPE_LEVEL_HIGH>;
			interrupt-names = "macirq", "sfty";

			iommus = <&apps_smmu 0x140 0xf>;
			dma-coherent;

			snps,tso;
			snps,pbl = <32>;
			rx-fifo-depth = <16384>;
			tx-fifo-depth = <16384>;

			status = "disabled";
		};

		ethernet0: ethernet@23040000 {
			compatible = "qcom,sa8775p-ethqos";
			reg = <0x0 0x23040000 0x0 0x10000>,
			      <0x0 0x23056000 0x0 0x100>;
			reg-names = "stmmaceth", "rgmii";

			interrupts = <GIC_SPI 946 IRQ_TYPE_LEVEL_HIGH>,
				     <GIC_SPI 782 IRQ_TYPE_LEVEL_HIGH>;
			interrupt-names = "macirq", "sfty";

			iommus = <&apps_smmu 0x120 0xf>;
			dma-coherent;

			snps,tso;
			snps,pbl = <32>;
			rx-fifo-depth = <16384>;
			tx-fifo-depth = <16384>;

			status = "disabled";
		};

		remoteproc_cdsp0: remoteproc@26300000 {
			compatible = "qcom,sa8775p-cdsp0-pas";
			reg = <0x0 0x26300000 0x0 0x10000>;

			interrupts-extended = <&intc GIC_SPI 578 IRQ_TYPE_EDGE_RISING>,
					      <&smp2p_cdsp0_in 0 IRQ_TYPE_EDGE_RISING>,
					      <&smp2p_cdsp0_in 1 IRQ_TYPE_EDGE_RISING>,
					      <&smp2p_cdsp0_in 2 IRQ_TYPE_EDGE_RISING>,
					      <&smp2p_cdsp0_in 3 IRQ_TYPE_EDGE_RISING>;
			interrupt-names = "wdog", "fatal", "ready",
					  "handover", "stop-ack";

			memory-region = <&pil_cdsp0_mem>;

			qcom,qmp = <&aoss_qmp>;

			qcom,smem-states = <&smp2p_cdsp0_out 0>;
			qcom,smem-state-names = "stop";

			#cooling-cells = <3>;

			status = "disabled";

			glink-edge {
				interrupts-extended = <&ipcc IPCC_CLIENT_CDSP
							     IPCC_MPROC_SIGNAL_GLINK_QMP
							     IRQ_TYPE_EDGE_RISING>;
				mboxes = <&ipcc IPCC_CLIENT_CDSP
						IPCC_MPROC_SIGNAL_GLINK_QMP>;

				label = "cdsp";
				qcom,remote-pid = <5>;

				fastrpc {
					compatible = "qcom,fastrpc";
					qcom,glink-channels = "fastrpcglink-apps-dsp";
					label = "cdsp";
					#address-cells = <1>;
					#size-cells = <0>;

					compute-cb@1 {
						compatible = "qcom,fastrpc-compute-cb";
						reg = <1>;
						iommus = <&apps_smmu 0x2141 0x04a0>,
							 <&apps_smmu 0x2181 0x0400>;
						dma-coherent;
					};

					compute-cb@2 {
						compatible = "qcom,fastrpc-compute-cb";
						reg = <2>;
						iommus = <&apps_smmu 0x2142 0x04a0>,
							 <&apps_smmu 0x2182 0x0400>;
						dma-coherent;
					};

					compute-cb@3 {
						compatible = "qcom,fastrpc-compute-cb";
						reg = <3>;
						iommus = <&apps_smmu 0x2143 0x04a0>,
							 <&apps_smmu 0x2183 0x0400>;
						dma-coherent;
					};

					compute-cb@4 {
						compatible = "qcom,fastrpc-compute-cb";
						reg = <4>;
						iommus = <&apps_smmu 0x2144 0x04a0>,
							 <&apps_smmu 0x2184 0x0400>;
						dma-coherent;
					};

					compute-cb@5 {
						compatible = "qcom,fastrpc-compute-cb";
						reg = <5>;
						iommus = <&apps_smmu 0x2145 0x04a0>,
							 <&apps_smmu 0x2185 0x0400>;
						dma-coherent;
					};

					compute-cb@6 {
						compatible = "qcom,fastrpc-compute-cb";
						reg = <6>;
						iommus = <&apps_smmu 0x2146 0x04a0>,
							 <&apps_smmu 0x2186 0x0400>;
						dma-coherent;
					};

					compute-cb@7 {
						compatible = "qcom,fastrpc-compute-cb";
						reg = <7>;
						iommus = <&apps_smmu 0x2147 0x04a0>,
							 <&apps_smmu 0x2187 0x0400>;
						dma-coherent;
					};

					compute-cb@8 {
						compatible = "qcom,fastrpc-compute-cb";
						reg = <8>;
						iommus = <&apps_smmu 0x2148 0x04a0>,
							 <&apps_smmu 0x2188 0x0400>;
						dma-coherent;
					};

					compute-cb@9 {
						compatible = "qcom,fastrpc-compute-cb";
						reg = <9>;
						iommus = <&apps_smmu 0x2149 0x04a0>,
							 <&apps_smmu 0x2189 0x0400>;
						dma-coherent;
					};

					compute-cb@11 {
						compatible = "qcom,fastrpc-compute-cb";
						reg = <11>;
						iommus = <&apps_smmu 0x214b 0x04a0>,
							 <&apps_smmu 0x218b 0x0400>;
						dma-coherent;
					};
				};
			};
		};

		remoteproc_cdsp1: remoteproc@2a300000 {
			compatible = "qcom,sa8775p-cdsp1-pas";
			reg = <0x0 0x2a300000 0x0 0x10000>;

			interrupts-extended = <&intc GIC_SPI 798 IRQ_TYPE_EDGE_RISING>,
					      <&smp2p_cdsp1_in 0 IRQ_TYPE_EDGE_RISING>,
					      <&smp2p_cdsp1_in 1 IRQ_TYPE_EDGE_RISING>,
					      <&smp2p_cdsp1_in 2 IRQ_TYPE_EDGE_RISING>,
					      <&smp2p_cdsp1_in 3 IRQ_TYPE_EDGE_RISING>;
			interrupt-names = "wdog", "fatal", "ready",
					  "handover", "stop-ack";

			memory-region = <&pil_cdsp1_mem>;

			qcom,qmp = <&aoss_qmp>;

			qcom,smem-states = <&smp2p_cdsp1_out 0>;
			qcom,smem-state-names = "stop";

			#cooling-cells = <3>;

			status = "disabled";

			glink-edge {
				interrupts-extended = <&ipcc IPCC_CLIENT_NSP1
							     IPCC_MPROC_SIGNAL_GLINK_QMP
							     IRQ_TYPE_EDGE_RISING>;
				mboxes = <&ipcc IPCC_CLIENT_NSP1
						IPCC_MPROC_SIGNAL_GLINK_QMP>;

				label = "cdsp";
				qcom,remote-pid = <12>;

				fastrpc {
					compatible = "qcom,fastrpc";
					qcom,glink-channels = "fastrpcglink-apps-dsp";
					label = "cdsp1";
					#address-cells = <1>;
					#size-cells = <0>;

					compute-cb@1 {
						compatible = "qcom,fastrpc-compute-cb";
						reg = <1>;
						iommus = <&apps_smmu 0x2941 0x04a0>,
							 <&apps_smmu 0x2981 0x0400>;
						dma-coherent;
					};

					compute-cb@2 {
						compatible = "qcom,fastrpc-compute-cb";
						reg = <2>;
						iommus = <&apps_smmu 0x2942 0x04a0>,
							 <&apps_smmu 0x2982 0x0400>;
						dma-coherent;
					};

					compute-cb@3 {
						compatible = "qcom,fastrpc-compute-cb";
						reg = <3>;
						iommus = <&apps_smmu 0x2943 0x04a0>,
							 <&apps_smmu 0x2983 0x0400>;
						dma-coherent;
					};

					compute-cb@4 {
						compatible = "qcom,fastrpc-compute-cb";
						reg = <4>;
						iommus = <&apps_smmu 0x2944 0x04a0>,
							 <&apps_smmu 0x2984 0x0400>;
						dma-coherent;
					};

					compute-cb@5 {
						compatible = "qcom,fastrpc-compute-cb";
						reg = <5>;
						iommus = <&apps_smmu 0x2945 0x04a0>,
							 <&apps_smmu 0x2985 0x0400>;
						dma-coherent;
					};

					compute-cb@6 {
						compatible = "qcom,fastrpc-compute-cb";
						reg = <6>;
						iommus = <&apps_smmu 0x2946 0x04a0>,
							 <&apps_smmu 0x2986 0x0400>;
						dma-coherent;
					};

					compute-cb@7 {
						compatible = "qcom,fastrpc-compute-cb";
						reg = <7>;
						iommus = <&apps_smmu 0x2947 0x04a0>,
							 <&apps_smmu 0x2987 0x0400>;
						dma-coherent;
					};

					compute-cb@8 {
						compatible = "qcom,fastrpc-compute-cb";
						reg = <8>;
						iommus = <&apps_smmu 0x2948 0x04a0>,
							 <&apps_smmu 0x2988 0x0400>;
						dma-coherent;
					};

					compute-cb@9 {
						compatible = "qcom,fastrpc-compute-cb";
						reg = <9>;
						iommus = <&apps_smmu 0x2949 0x04a0>,
							 <&apps_smmu 0x2989 0x0400>;
						dma-coherent;
					};

					compute-cb@10 {
						compatible = "qcom,fastrpc-compute-cb";
						reg = <10>;
						iommus = <&apps_smmu 0x294a 0x04a0>,
							 <&apps_smmu 0x298a 0x0400>;
						dma-coherent;
					};

					compute-cb@11 {
						compatible = "qcom,fastrpc-compute-cb";
						reg = <11>;
						iommus = <&apps_smmu 0x294b 0x04a0>,
							 <&apps_smmu 0x298b 0x0400>;
						dma-coherent;
					};

					compute-cb@12 {
						compatible = "qcom,fastrpc-compute-cb";
						reg = <12>;
						iommus = <&apps_smmu 0x294c 0x04a0>,
							 <&apps_smmu 0x298c 0x0400>;
						dma-coherent;
					};

					compute-cb@13 {
						compatible = "qcom,fastrpc-compute-cb";
						reg = <13>;
						iommus = <&apps_smmu 0x294d 0x04a0>,
							 <&apps_smmu 0x298d 0x0400>;
						dma-coherent;
					};
				};
			};
		};

		remoteproc_adsp: remoteproc@30000000 {
			compatible = "qcom,sa8775p-adsp-pas";
			reg = <0x0 0x30000000 0x0 0x100>;

			interrupts-extended = <&pdc 6 IRQ_TYPE_EDGE_RISING>,
					      <&smp2p_adsp_in 0 IRQ_TYPE_EDGE_RISING>,
					      <&smp2p_adsp_in 1 IRQ_TYPE_EDGE_RISING>,
					      <&smp2p_adsp_in 2 IRQ_TYPE_EDGE_RISING>,
					      <&smp2p_adsp_in 3 IRQ_TYPE_EDGE_RISING>;
			interrupt-names = "wdog", "fatal", "ready", "handover",
					  "stop-ack";

			memory-region = <&pil_adsp_mem>;

			qcom,qmp = <&aoss_qmp>;

			qcom,smem-states = <&smp2p_adsp_out 0>;
			qcom,smem-state-names = "stop";

			status = "disabled";

			glink-edge {
				interrupts-extended = <&ipcc IPCC_CLIENT_LPASS
							     IPCC_MPROC_SIGNAL_GLINK_QMP
							     IRQ_TYPE_EDGE_RISING>;
				mboxes = <&ipcc IPCC_CLIENT_LPASS
						IPCC_MPROC_SIGNAL_GLINK_QMP>;

				label = "lpass";
				qcom,remote-pid = <2>;

				fastrpc {
					compatible = "qcom,fastrpc";
					qcom,glink-channels = "fastrpcglink-apps-dsp";
					label = "adsp";
					memory-region = <&adsp_rpc_remote_heap_mem>;
					qcom,vmids = <QCOM_SCM_VMID_LPASS
							  QCOM_SCM_VMID_ADSP_HEAP>;
					#address-cells = <1>;
					#size-cells = <0>;

					compute-cb@3 {
						compatible = "qcom,fastrpc-compute-cb";
						reg = <3>;
						iommus = <&apps_smmu 0x3003 0x0>;
						dma-coherent;
					};

					compute-cb@4 {
						compatible = "qcom,fastrpc-compute-cb";
						reg = <4>;
						iommus = <&apps_smmu 0x3004 0x0>;
						dma-coherent;
					};

					compute-cb@5 {
						compatible = "qcom,fastrpc-compute-cb";
						reg = <5>;
						iommus = <&apps_smmu 0x3005 0x0>;
						qcom,nsessions = <5>;
						dma-coherent;
					};
				};

				gpr {
					compatible = "qcom,gpr";
					qcom,glink-channels = "adsp_apps";
					qcom,domain = <GPR_DOMAIN_ID_ADSP>;
					qcom,intents = <512 20>;
					#address-cells = <1>;
					#size-cells = <0>;

					q6apm: service@1 {
						compatible = "qcom,q6apm";
						reg = <GPR_APM_MODULE_IID>;
						#sound-dai-cells = <0>;
						qcom,protection-domain = "avs/audio",
									 "msm/adsp/audio_pd";

						q6apmbedai: bedais {
							compatible = "qcom,q6apm-lpass-dais";
							#sound-dai-cells = <1>;
						};

						q6apmdai: dais {
							compatible = "qcom,q6apm-dais";
							iommus = <&apps_smmu 0x3001 0x0>;
						};
					};

					q6prm: service@2 {
						compatible = "qcom,q6prm";
						reg = <GPR_PRM_MODULE_IID>;
						qcom,protection-domain = "avs/audio",
									 "msm/adsp/audio_pd";

						q6prmcc: clock-controller {
							compatible = "qcom,q6prm-lpass-clocks";
							#clock-cells = <2>;
						};
					};
				};
			};
		};
	};

	thermal-zones {
		aoss-0-thermal {
			thermal-sensors = <&tsens0 0>;

			trips {
				trip-point0 {
					temperature = <105000>;
					hysteresis = <5000>;
					type = "passive";
				};

				trip-point1 {
					temperature = <115000>;
					hysteresis = <5000>;
					type = "passive";
				};
			};
		};

		cpu-0-0-0-thermal {
			polling-delay-passive = <10>;

			thermal-sensors = <&tsens0 1>;

			trips {
				trip-point0 {
					temperature = <105000>;
					hysteresis = <5000>;
					type = "passive";
				};

				trip-point1 {
					temperature = <115000>;
					hysteresis = <5000>;
					type = "passive";
				};
			};
		};

		cpu-0-1-0-thermal {
			polling-delay-passive = <10>;

			thermal-sensors = <&tsens0 2>;

			trips {
				trip-point0 {
					temperature = <105000>;
					hysteresis = <5000>;
					type = "passive";
				};

				trip-point1 {
					temperature = <115000>;
					hysteresis = <5000>;
					type = "passive";
				};
			};
		};

		cpu-0-2-0-thermal {
			polling-delay-passive = <10>;

			thermal-sensors = <&tsens0 3>;

			trips {
				trip-point0 {
					temperature = <105000>;
					hysteresis = <5000>;
					type = "passive";
				};

				trip-point1 {
					temperature = <115000>;
					hysteresis = <5000>;
					type = "passive";
				};
			};
		};

		cpu-0-3-0-thermal {
			polling-delay-passive = <10>;

			thermal-sensors = <&tsens0 4>;

			trips {
				trip-point0 {
					temperature = <105000>;
					hysteresis = <5000>;
					type = "passive";
				};

				trip-point1 {
					temperature = <115000>;
					hysteresis = <5000>;
					type = "passive";
				};
			};
		};

		gpuss-0-thermal {
			polling-delay-passive = <10>;

			thermal-sensors = <&tsens0 5>;

			cooling-maps {
				map0 {
					trip = <&gpuss0_alert0>;
					cooling-device = <&gpu THERMAL_NO_LIMIT THERMAL_NO_LIMIT>;
				};
			};

			trips {
				gpuss0_alert0: trip-point0 {
					temperature = <105000>;
					hysteresis = <5000>;
					type = "passive";
				};

				trip-point1 {
					temperature = <115000>;
					hysteresis = <5000>;
					type = "passive";
				};
			};
		};

		gpuss-1-thermal {
			polling-delay-passive = <10>;

			thermal-sensors = <&tsens0 6>;

			cooling-maps {
				map0 {
					trip = <&gpuss1_alert0>;
					cooling-device = <&gpu THERMAL_NO_LIMIT THERMAL_NO_LIMIT>;
				};
			};

			trips {
				gpuss1_alert0: trip-point0 {
					temperature = <105000>;
					hysteresis = <5000>;
					type = "passive";
				};

				trip-point1 {
					temperature = <115000>;
					hysteresis = <5000>;
					type = "passive";
				};
			};
		};

		gpuss-2-thermal {
			polling-delay-passive = <10>;

			thermal-sensors = <&tsens0 7>;

			cooling-maps {
				map0 {
					trip = <&gpuss2_alert0>;
					cooling-device = <&gpu THERMAL_NO_LIMIT THERMAL_NO_LIMIT>;
				};
			};

			trips {
				gpuss2_alert0: trip-point0 {
					temperature = <105000>;
					hysteresis = <5000>;
					type = "passive";
				};

				trip-point1 {
					temperature = <115000>;
					hysteresis = <5000>;
					type = "passive";
				};
			};
		};

		audio-thermal {
			thermal-sensors = <&tsens0 8>;

			trips {
				trip-point0 {
					temperature = <105000>;
					hysteresis = <5000>;
					type = "passive";
				};

				trip-point1 {
					temperature = <115000>;
					hysteresis = <5000>;
					type = "passive";
				};
			};
		};

		camss-0-thermal {
			thermal-sensors = <&tsens0 9>;

			trips {
				trip-point0 {
					temperature = <105000>;
					hysteresis = <5000>;
					type = "passive";
				};

				trip-point1 {
					temperature = <115000>;
					hysteresis = <5000>;
					type = "passive";
				};
			};
		};

		pcie-0-thermal {
			thermal-sensors = <&tsens0 10>;

			trips {
				trip-point0 {
					temperature = <105000>;
					hysteresis = <5000>;
					type = "passive";
				};

				trip-point1 {
					temperature = <115000>;
					hysteresis = <5000>;
					type = "passive";
				};
			};
		};

		cpuss-0-0-thermal {
			thermal-sensors = <&tsens0 11>;

			trips {
				trip-point0 {
					temperature = <105000>;
					hysteresis = <5000>;
					type = "passive";
				};

				trip-point1 {
					temperature = <115000>;
					hysteresis = <5000>;
					type = "passive";
				};
			};
		};

		aoss-1-thermal {
			thermal-sensors = <&tsens1 0>;

			trips {
				trip-point0 {
					temperature = <105000>;
					hysteresis = <5000>;
					type = "passive";
				};

				trip-point1 {
					temperature = <115000>;
					hysteresis = <5000>;
					type = "passive";
				};
			};
		};

		cpu-0-0-1-thermal {
			polling-delay-passive = <10>;

			thermal-sensors = <&tsens1 1>;

			trips {
				trip-point0 {
					temperature = <105000>;
					hysteresis = <5000>;
					type = "passive";
				};

				trip-point1 {
					temperature = <115000>;
					hysteresis = <5000>;
					type = "passive";
				};
			};
		};

		cpu-0-1-1-thermal {
			polling-delay-passive = <10>;

			thermal-sensors = <&tsens1 2>;

			trips {
				trip-point0 {
					temperature = <105000>;
					hysteresis = <5000>;
					type = "passive";
				};

				trip-point1 {
					temperature = <115000>;
					hysteresis = <5000>;
					type = "passive";
				};
			};
		};

		cpu-0-2-1-thermal {
			polling-delay-passive = <10>;

			thermal-sensors = <&tsens1 3>;

			trips {
				trip-point0 {
					temperature = <105000>;
					hysteresis = <5000>;
					type = "passive";
				};

				trip-point1 {
					temperature = <115000>;
					hysteresis = <5000>;
					type = "passive";
				};
			};
		};

		cpu-0-3-1-thermal {
			polling-delay-passive = <10>;

			thermal-sensors = <&tsens1 4>;

			trips {
				trip-point0 {
					temperature = <105000>;
					hysteresis = <5000>;
					type = "passive";
				};

				trip-point1 {
					temperature = <115000>;
					hysteresis = <5000>;
					type = "passive";
				};
			};
		};

		gpuss-3-thermal {
			polling-delay-passive = <10>;

			thermal-sensors = <&tsens1 5>;

			cooling-maps {
				map0 {
					trip = <&gpuss3_alert0>;
					cooling-device = <&gpu THERMAL_NO_LIMIT THERMAL_NO_LIMIT>;
				};
			};

			trips {
				gpuss3_alert0: trip-point0 {
					temperature = <105000>;
					hysteresis = <5000>;
					type = "passive";
				};

				trip-point1 {
					temperature = <115000>;
					hysteresis = <5000>;
					type = "passive";
				};
			};
		};

		gpuss-4-thermal {
			polling-delay-passive = <10>;

			thermal-sensors = <&tsens1 6>;

			cooling-maps {
				map0 {
					trip = <&gpuss4_alert0>;
					cooling-device = <&gpu THERMAL_NO_LIMIT THERMAL_NO_LIMIT>;
				};
			};

			trips {
				gpuss4_alert0: trip-point0 {
					temperature = <105000>;
					hysteresis = <5000>;
					type = "passive";
				};

				trip-point1 {
					temperature = <115000>;
					hysteresis = <5000>;
					type = "passive";
				};
			};
		};

		gpuss-5-thermal {
			polling-delay-passive = <10>;

			thermal-sensors = <&tsens1 7>;

			cooling-maps {
				map0 {
					trip = <&gpuss5_alert0>;
					cooling-device = <&gpu THERMAL_NO_LIMIT THERMAL_NO_LIMIT>;
				};
			};

			trips {
				gpuss5_alert0: trip-point0 {
					temperature = <105000>;
					hysteresis = <5000>;
					type = "passive";
				};

				trip-point1 {
					temperature = <115000>;
					hysteresis = <5000>;
					type = "passive";
				};
			};
		};

		video-thermal {
			thermal-sensors = <&tsens1 8>;

			trips {
				trip-point0 {
					temperature = <105000>;
					hysteresis = <5000>;
					type = "passive";
				};

				trip-point1 {
					temperature = <115000>;
					hysteresis = <5000>;
					type = "passive";
				};
			};
		};

		camss-1-thermal {
			thermal-sensors = <&tsens1 9>;

			trips {
				trip-point0 {
					temperature = <105000>;
					hysteresis = <5000>;
					type = "passive";
				};

				trip-point1 {
					temperature = <115000>;
					hysteresis = <5000>;
					type = "passive";
				};
			};
		};

		pcie-1-thermal {
			thermal-sensors = <&tsens1 10>;

			trips {
				trip-point0 {
					temperature = <105000>;
					hysteresis = <5000>;
					type = "passive";
				};

				trip-point1 {
					temperature = <115000>;
					hysteresis = <5000>;
					type = "passive";
				};
			};
		};

		cpuss-0-1-thermal {
			thermal-sensors = <&tsens1 11>;

			trips {
				trip-point0 {
					temperature = <105000>;
					hysteresis = <5000>;
					type = "passive";
				};

				trip-point1 {
					temperature = <115000>;
					hysteresis = <5000>;
					type = "passive";
				};
			};
		};

		aoss-2-thermal {
			thermal-sensors = <&tsens2 0>;

			trips {
				trip-point0 {
					temperature = <105000>;
					hysteresis = <5000>;
					type = "passive";
				};

				trip-point1 {
					temperature = <115000>;
					hysteresis = <5000>;
					type = "passive";
				};
			};
		};

		cpu-1-0-0-thermal {
			polling-delay-passive = <10>;

			thermal-sensors = <&tsens2 1>;

			trips {
				trip-point0 {
					temperature = <105000>;
					hysteresis = <5000>;
					type = "passive";
				};

				trip-point1 {
					temperature = <115000>;
					hysteresis = <5000>;
					type = "passive";
				};
			};
		};

		cpu-1-1-0-thermal {
			polling-delay-passive = <10>;

			thermal-sensors = <&tsens2 2>;

			trips {
				trip-point0 {
					temperature = <105000>;
					hysteresis = <5000>;
					type = "passive";
				};

				trip-point1 {
					temperature = <115000>;
					hysteresis = <5000>;
					type = "passive";
				};
			};
		};

		cpu-1-2-0-thermal {
			polling-delay-passive = <10>;

			thermal-sensors = <&tsens2 3>;

			trips {
				trip-point0 {
					temperature = <105000>;
					hysteresis = <5000>;
					type = "passive";
				};

				trip-point1 {
					temperature = <115000>;
					hysteresis = <5000>;
					type = "passive";
				};
			};
		};

		cpu-1-3-0-thermal {
			polling-delay-passive = <10>;

			thermal-sensors = <&tsens2 4>;

			trips {
				trip-point0 {
					temperature = <105000>;
					hysteresis = <5000>;
					type = "passive";
				};

				trip-point1 {
					temperature = <115000>;
					hysteresis = <5000>;
					type = "passive";
				};
			};
		};

		nsp-0-0-0-thermal {
			polling-delay-passive = <10>;

			thermal-sensors = <&tsens2 5>;

			trips {
				nsp_0_0_0_alert0: trip-point0 {
					temperature = <105000>;
					hysteresis = <5000>;
					type = "passive";
				};

				trip-point1 {
					temperature = <115000>;
					hysteresis = <5000>;
					type = "passive";
				};
			};

			cooling-maps {
				map0 {
					trip = <&nsp_0_0_0_alert0>;
					cooling-device = <&remoteproc_cdsp0 QCOM_TMD_CDSP_SW
							 THERMAL_NO_LIMIT THERMAL_NO_LIMIT>;
				};
			};
		};

		nsp-0-1-0-thermal {
			polling-delay-passive = <10>;

			thermal-sensors = <&tsens2 6>;

			trips {
				nsp_0_1_0_alert0: trip-point0 {
					temperature = <105000>;
					hysteresis = <5000>;
					type = "passive";
				};

				trip-point1 {
					temperature = <115000>;
					hysteresis = <5000>;
					type = "passive";
				};
			};

			cooling-maps {
				map0 {
					trip = <&nsp_0_1_0_alert0>;
					cooling-device = <&remoteproc_cdsp0 QCOM_TMD_CDSP_SW
							 THERMAL_NO_LIMIT THERMAL_NO_LIMIT>;
				};
			};
		};

		nsp-0-2-0-thermal {
			polling-delay-passive = <10>;

			thermal-sensors = <&tsens2 7>;

			trips {
				nsp_0_2_0_alert0: trip-point0 {
					temperature = <105000>;
					hysteresis = <5000>;
					type = "passive";
				};

				trip-point1 {
					temperature = <115000>;
					hysteresis = <5000>;
					type = "passive";
				};
			};

			cooling-maps {
				map0 {
					trip = <&nsp_0_2_0_alert0>;
					cooling-device = <&remoteproc_cdsp0 QCOM_TMD_CDSP_SW
							 THERMAL_NO_LIMIT THERMAL_NO_LIMIT>;
				};
			};
		};

		nsp-1-0-0-thermal {
			polling-delay-passive = <10>;

			thermal-sensors = <&tsens2 8>;

			trips {
				nsp_1_0_0_alert0: trip-point0 {
					temperature = <105000>;
					hysteresis = <5000>;
					type = "passive";
				};

				trip-point1 {
					temperature = <115000>;
					hysteresis = <5000>;
					type = "passive";
				};
			};

			cooling-maps {
				map0 {
					trip = <&nsp_1_0_0_alert0>;
					cooling-device = <&remoteproc_cdsp1 QCOM_TMD_CDSP_SW
							 THERMAL_NO_LIMIT THERMAL_NO_LIMIT>;
				};
			};
		};

		nsp-1-1-0-thermal {
			polling-delay-passive = <10>;

			thermal-sensors = <&tsens2 9>;

			trips {
				nsp_1_1_0_alert0: trip-point0 {
					temperature = <105000>;
					hysteresis = <5000>;
					type = "passive";
				};

				trip-point1 {
					temperature = <115000>;
					hysteresis = <5000>;
					type = "passive";
				};
			};

			cooling-maps {
				map0 {
					trip = <&nsp_1_1_0_alert0>;
					cooling-device = <&remoteproc_cdsp1 QCOM_TMD_CDSP_SW
							 THERMAL_NO_LIMIT THERMAL_NO_LIMIT>;
				};
			};
		};

		nsp-1-2-0-thermal {
			polling-delay-passive = <10>;

			thermal-sensors = <&tsens2 10>;

			trips {
				nsp_1_2_0_alert0: trip-point0 {
					temperature = <105000>;
					hysteresis = <5000>;
					type = "passive";
				};

				trip-point1 {
					temperature = <115000>;
					hysteresis = <5000>;
					type = "passive";
				};
			};

			cooling-maps {
				map0 {
					trip = <&nsp_1_2_0_alert0>;
					cooling-device = <&remoteproc_cdsp1 QCOM_TMD_CDSP_SW
							 THERMAL_NO_LIMIT THERMAL_NO_LIMIT>;
				};
			};
		};

		ddrss-0-thermal {
			thermal-sensors = <&tsens2 11>;

			trips {
				trip-point0 {
					temperature = <105000>;
					hysteresis = <5000>;
					type = "passive";
				};

				trip-point1 {
					temperature = <115000>;
					hysteresis = <5000>;
					type = "passive";
				};
			};
		};

		cpuss-1-0-thermal {
			thermal-sensors = <&tsens2 12>;

			trips {
				trip-point0 {
					temperature = <105000>;
					hysteresis = <5000>;
					type = "passive";
				};

				trip-point1 {
					temperature = <115000>;
					hysteresis = <5000>;
					type = "passive";
				};
			};
		};

		aoss-3-thermal {
			thermal-sensors = <&tsens3 0>;

			trips {
				trip-point0 {
					temperature = <105000>;
					hysteresis = <5000>;
					type = "passive";
				};

				trip-point1 {
					temperature = <115000>;
					hysteresis = <5000>;
					type = "passive";
				};
			};
		};

		cpu-1-0-1-thermal {
			polling-delay-passive = <10>;

			thermal-sensors = <&tsens3 1>;

			trips {
				trip-point0 {
					temperature = <105000>;
					hysteresis = <5000>;
					type = "passive";
				};

				trip-point1 {
					temperature = <115000>;
					hysteresis = <5000>;
					type = "passive";
				};
			};
		};

		cpu-1-1-1-thermal {
			polling-delay-passive = <10>;

			thermal-sensors = <&tsens3 2>;

			trips {
				trip-point0 {
					temperature = <105000>;
					hysteresis = <5000>;
					type = "passive";
				};

				trip-point1 {
					temperature = <115000>;
					hysteresis = <5000>;
					type = "passive";
				};
			};
		};

		cpu-1-2-1-thermal {
			polling-delay-passive = <10>;

			thermal-sensors = <&tsens3 3>;

			trips {
				trip-point0 {
					temperature = <105000>;
					hysteresis = <5000>;
					type = "passive";
				};

				trip-point1 {
					temperature = <115000>;
					hysteresis = <5000>;
					type = "passive";
				};
			};
		};

		cpu-1-3-1-thermal {
			polling-delay-passive = <10>;

			thermal-sensors = <&tsens3 4>;

			trips {
				trip-point0 {
					temperature = <105000>;
					hysteresis = <5000>;
					type = "passive";
				};

				trip-point1 {
					temperature = <115000>;
					hysteresis = <5000>;
					type = "passive";
				};
			};
		};

		nsp-0-0-1-thermal {
			polling-delay-passive = <10>;

			thermal-sensors = <&tsens3 5>;

			trips {
				nsp_0_0_1_alert0: trip-point0 {
					temperature = <105000>;
					hysteresis = <5000>;
					type = "passive";
				};

				trip-point1 {
					temperature = <115000>;
					hysteresis = <5000>;
					type = "passive";
				};
			};

			cooling-maps {
				map0 {
					trip = <&nsp_0_0_1_alert0>;
					cooling-device = <&remoteproc_cdsp0 QCOM_TMD_CDSP_SW
							 THERMAL_NO_LIMIT THERMAL_NO_LIMIT>;
				};
			};
		};

		nsp-0-1-1-thermal {
			polling-delay-passive = <10>;

			thermal-sensors = <&tsens3 6>;

			trips {
				nsp_0_1_1_alert0: trip-point0 {
					temperature = <105000>;
					hysteresis = <5000>;
					type = "passive";
				};

				trip-point1 {
					temperature = <115000>;
					hysteresis = <5000>;
					type = "passive";
				};
			};

			cooling-maps {
				map0 {
					trip = <&nsp_0_1_1_alert0>;
					cooling-device = <&remoteproc_cdsp0 QCOM_TMD_CDSP_SW
							 THERMAL_NO_LIMIT THERMAL_NO_LIMIT>;
				};
			};
		};

		nsp-0-2-1-thermal {
			polling-delay-passive = <10>;

			thermal-sensors = <&tsens3 7>;

			trips {
				nsp_0_2_1_alert0: trip-point0 {
					temperature = <105000>;
					hysteresis = <5000>;
					type = "passive";
				};

				trip-point1 {
					temperature = <115000>;
					hysteresis = <5000>;
					type = "passive";
				};
			};

			cooling-maps {
				map0 {
					trip = <&nsp_0_2_1_alert0>;
					cooling-device = <&remoteproc_cdsp0 QCOM_TMD_CDSP_SW
							 THERMAL_NO_LIMIT THERMAL_NO_LIMIT>;
				};
			};
		};

		nsp-1-0-1-thermal {
			polling-delay-passive = <10>;

			thermal-sensors = <&tsens3 8>;

			trips {
				nsp_1_0_1_alert0: trip-point0 {
					temperature = <105000>;
					hysteresis = <5000>;
					type = "passive";
				};

				trip-point1 {
					temperature = <115000>;
					hysteresis = <5000>;
					type = "passive";
				};
			};

			cooling-maps {
				map0 {
					trip = <&nsp_1_0_1_alert0>;
					cooling-device = <&remoteproc_cdsp1 QCOM_TMD_CDSP_SW
							 THERMAL_NO_LIMIT THERMAL_NO_LIMIT>;
				};
			};
		};

		nsp-1-1-1-thermal {
			polling-delay-passive = <10>;

			thermal-sensors = <&tsens3 9>;

			trips {
				nsp_1_1_1_alert0: trip-point0 {
					temperature = <105000>;
					hysteresis = <5000>;
					type = "passive";
				};

				trip-point1 {
					temperature = <115000>;
					hysteresis = <5000>;
					type = "passive";
				};
			};

			cooling-maps {
				map0 {
					trip = <&nsp_1_1_1_alert0>;
					cooling-device = <&remoteproc_cdsp1 QCOM_TMD_CDSP_SW
							 THERMAL_NO_LIMIT THERMAL_NO_LIMIT>;
				};
			};
		};

		nsp-1-2-1-thermal {
			polling-delay-passive = <10>;

			thermal-sensors = <&tsens3 10>;

			trips {
				nsp_1_2_1_alert0: trip-point0 {
					temperature = <105000>;
					hysteresis = <5000>;
					type = "passive";
				};

				trip-point1 {
					temperature = <115000>;
					hysteresis = <5000>;
					type = "passive";
				};
			};

			cooling-maps {
				map0 {
					trip = <&nsp_1_2_1_alert0>;
					cooling-device = <&remoteproc_cdsp1 QCOM_TMD_CDSP_SW
							 THERMAL_NO_LIMIT THERMAL_NO_LIMIT>;
				};
			};
		};

		ddrss-1-thermal {
			thermal-sensors = <&tsens3 11>;

			trips {
				trip-point0 {
					temperature = <105000>;
					hysteresis = <5000>;
					type = "passive";
				};

				trip-point1 {
					temperature = <115000>;
					hysteresis = <5000>;
					type = "passive";
				};
			};
		};

		cpuss-1-1-thermal {
			thermal-sensors = <&tsens3 12>;

			trips {
				trip-point0 {
					temperature = <105000>;
					hysteresis = <5000>;
					type = "passive";
				};

				trip-point1 {
					temperature = <115000>;
					hysteresis = <5000>;
					type = "passive";
				};
			};
		};
	};

	arch_timer: timer {
		compatible = "arm,armv8-timer";
		interrupts = <GIC_PPI 13 IRQ_TYPE_LEVEL_LOW>,
			     <GIC_PPI 14 IRQ_TYPE_LEVEL_LOW>,
			     <GIC_PPI 11 IRQ_TYPE_LEVEL_LOW>,
			     <GIC_PPI 10 IRQ_TYPE_LEVEL_LOW>;
	};

	turing-llm-tpdm {
		compatible = "qcom,coresight-static-tpdm";
		label = "tpdm_cdsp_llm_0";

		qcom,cmb-element-bits = <32>;

		out-ports {
			port {
				turing_llm_tpdm_out: endpoint {
					remote-endpoint = <&turing0_funnel_in1>;
				};
			};
		};
	};
};
